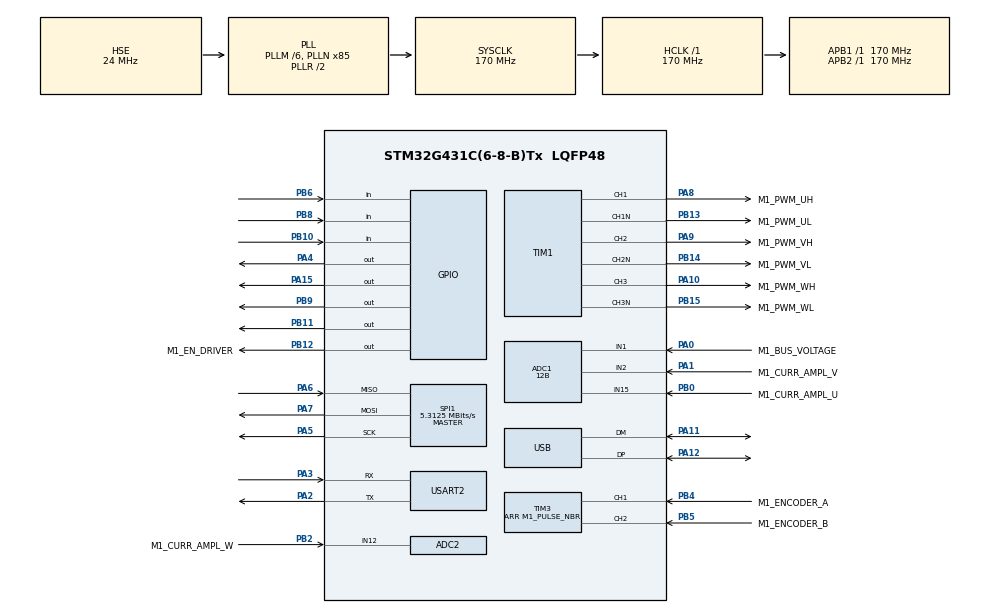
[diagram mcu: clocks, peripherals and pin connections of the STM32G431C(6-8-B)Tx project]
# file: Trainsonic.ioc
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ADC1.Channel-1\#ChannelRegularConversion=ADC_CHANNEL_1
ADC1.ClockPrescaler=ADC_CLOCK_ASYNC_DIV1
ADC1.ContinuousConvMode=DISABLE
ADC1.DMAContinuousRequests=DISABLE
ADC1.DataAlign=ADC_DATAALIGN_LEFT
ADC1.DiscontinuousConvMode=DISABLE
ADC1.EOCSelection=ADC_EOC_SINGLE_CONV
ADC1.EnableAnalogWatchDog1=false
ADC1.EnableAnalogWatchDog2=false
ADC1.EnableAnalogWatchDog3=false
ADC1.EnableInjectedConversion=ENABLE
ADC1.EnableRegularConversion=ENABLE
ADC1.ExternalTrigConv=ADC_SOFTWARE_START
ADC1.ExternalTrigConvEdge=ADC_EXTERNALTRIGCONVEDGE_NONE
ADC1.ExternalTrigInjecConv=ADC_EXTERNALTRIGINJEC_T1_TRGO
ADC1.ExternalTrigInjecConvEdge=ADC_EXTERNALTRIGINJECCONV_EDGE_RISING
ADC1.InjNumberOfConversion=2
ADC1.InjectedChannel-1\#ChannelInjectedConversion=ADC_CHANNEL_15
ADC1.InjectedChannel-2\#ChannelInjectedConversion=ADC_CHANNEL_2
ADC1.InjectedConvMode=None
ADC1.InjectedOffset-1\#ChannelInjectedConversion=0
ADC1.InjectedOffset-2\#ChannelInjectedConversion=0
ADC1.InjectedOffsetNumber-1\#ChannelInjectedConversion=ADC_OFFSET_NONE
ADC1.InjectedOffsetNumber-2\#ChannelInjectedConversion=ADC_OFFSET_NONE
ADC1.InjectedRank-1\#ChannelInjectedConversion=1
ADC1.InjectedRank-2\#ChannelInjectedConversion=2
ADC1.InjectedSamplingTime-1\#ChannelInjectedConversion=ADC_SAMPLETIME_6CYCLES_5
ADC1.InjectedSamplingTime-2\#ChannelInjectedConversion=ADC_SAMPLETIME_6CYCLES_5
ADC1.LowPowerAutoWait=DISABLE
ADC1.NbrOfConversion=1
ADC1.NbrOfConversionFlag=1
ADC1.Offset-1\#ChannelRegularConversion=0
ADC1.OffsetNumber-1\#ChannelRegularConversion=ADC_OFFSET_NONE
ADC1.Overrun=ADC_OVR_DATA_PRESERVED
ADC1.Rank-1\#ChannelRegularConversion=1
ADC1.Resolution=ADC_RESOLUTION_12B
ADC1.SamplingTime-1\#ChannelRegularConversion=ADC_SAMPLETIME_47CYCLES_5
ADC1.ScanConvMode=ADC_SCAN_ENABLE
ADC1.master=1
ADC2.ClockPrescaler=ADC_CLOCK_ASYNC_DIV1
ADC2.ContinuousConvMode=DISABLE
ADC2.DMAContinuousRequests=DISABLE
ADC2.DataAlign=ADC_DATAALIGN_LEFT
ADC2.DiscontinuousConvMode=DISABLE
ADC2.EOCSelection=ADC_EOC_SINGLE_CONV
ADC2.EnableAnalogWatchDog1=false
ADC2.EnableAnalogWatchDog2=false
ADC2.EnableAnalogWatchDog3=false
ADC2.EnableInjectedConversion=ENABLE
ADC2.EnableRegularConversion=DISABLE
ADC2.ExternalTrigInjecConv=ADC_EXTERNALTRIGINJEC_T1_TRGO
ADC2.ExternalTrigInjecConvEdge=ADC_EXTERNALTRIGINJECCONV_EDGE_RISING
ADC2.InjNumberOfConversion=2
ADC2.InjectedChannel-1\#ChannelInjectedConversion=ADC_CHANNEL_2
ADC2.InjectedChannel-2\#ChannelInjectedConversion=ADC_CHANNEL_12
ADC2.InjectedConvMode=None
ADC2.InjectedOffset-1\#ChannelInjectedConversion=0
ADC2.InjectedOffset-2\#ChannelInjectedConversion=0
ADC2.InjectedOffsetNumber-1\#ChannelInjectedConversion=ADC_OFFSET_NONE
ADC2.InjectedOffsetNumber-2\#ChannelInjectedConversion=ADC_OFFSET_NONE
ADC2.InjectedRank-1\#ChannelInjectedConversion=1
ADC2.InjectedRank-2\#ChannelInjectedConversion=2
ADC2.InjectedSamplingTime-1\#ChannelInjectedConversion=ADC_SAMPLETIME_6CYCLES_5
ADC2.InjectedSamplingTime-2\#ChannelInjectedConversion=ADC_SAMPLETIME_6CYCLES_5
ADC2.LowPowerAutoWait=DISABLE
ADC2.Overrun=ADC_OVR_DATA_PRESERVED
ADC2.Resolution=ADC_RESOLUTION_12B
ADC2.ScanConvMode=ADC_SCAN_ENABLE
ADC2.master=1
ExtraMW=MotorControl
ExtraMW.MotorControl.Config=MotorControl
ExtraMW.MotorControl.Mode=MotorControl
ExtraMW.MotorControl.Root=MCSDK_v6.4.2-Full/MotorControl
ExtraMW.MotorControl.Template=templates
FREERTOS.Tasks01=mediumFrequency,0,128,startMediumFrequencyTask,As weak,NULL,Dynamic,NULL,NULL;safety,1,128,StartSafetyTask,As external,NULL,Dynamic,NULL,NULL
FREERTOS.configUSE_NEWLIB_REENTRANT=1
Mcu.Family=STM32G4
Mcu.Name=STM32G431C(6-8-B)Tx
Mcu.Package=LQFP48
MotorControl.ADC_1_PERIPH=ADC1
MotorControl.ADC_2_PERIPH=ADC2
MotorControl.ADC_AHBPERIPH=RCC_AHBPeriph_ADC12
MotorControl.ADC_CLOCK_WB_DIV=1
MotorControl.ADC_PERIPH=ADC1
MotorControl.ADC_REFERENCE_VOLTAGE=3.3
MotorControl.BOARD=Trainsonic1
MotorControl.BUS_VOLTAGE_READING=true
MotorControl.CCMRAM_ENABLED=false
MotorControl.CLOCK_FREQUENCY=CPU_CLK_170_MHZ
MotorControl.CLOCK_SOURCE=EXTERNAL
MotorControl.CPU_CLK_170_MHZ=true
MotorControl.CTLBOARD_NAME=Trainsonic1
MotorControl.CUBE_MX_VER=6.17.0
MotorControl.CURRENT_READING_TOPOLOGY=THREE_SHUNT_INDEPENDENT_RESOURCES
MotorControl.CURR_SAMPLING_TIME=6
MotorControl.DBG_MCU_LOAD_MEASURE=false
MotorControl.DEBUG_DAC_FUNCTIONALITY_EN=false
MotorControl.DRIVES_NUMBER_SELECTION=SINGLEDRIVE
MotorControl.DRIVE_NUMBER=1
MotorControl.DRIVE_TYPE=FOC
MotorControl.ENCODER=true
MotorControl.ENCODER_AVAILABLE=true
MotorControl.ENCODER_PPR=1024
MotorControl.ENC_A_GPIO_PIN=LL_GPIO_PIN_4
MotorControl.ENC_A_GPIO_PORT=GPIOB
MotorControl.ENC_B_GPIO_PIN=LL_GPIO_PIN_5
MotorControl.ENC_B_GPIO_PORT=GPIOB
MotorControl.ENC_ICx_FILTER=128
MotorControl.ENC_INVERT_SPEED=false
MotorControl.ENC_TIMER_SELECTION=ENC_TIM3
MotorControl.ENC_USE_CH3=false
MotorControl.EN_DRIVER_AVAILABLE=true
MotorControl.EN_DRIVER_GPIO_PIN=LL_GPIO_PIN_12
MotorControl.EN_DRIVER_GPIO_PORT=GPIOB
MotorControl.EN_DRIVER_POLARITY=ACTIVE_HIGH
MotorControl.EXT_CLK_24_MHZ=true
MotorControl.EXT_CLOCK_FREQUENCY=EXT_CLK_24_MHZ
MotorControl.FEEDBACK_NET_FILTERING=false
MotorControl.FLASH_SIZE=128
MotorControl.HALL_SENSORS_AVAILABLE=false
MotorControl.HIGH_SIDE_IDLE_STATE=false
MotorControl.HWV_CS=ThreeShunt_AmplifiedCurrents
MotorControl.HWV_PWM=DrivingHighAndLowSidesAndMasterEnable
MotorControl.HW_COMPLEMENTED_LOW_SIDE=false
MotorControl.HW_DEAD_TIME_NS=400
MotorControl.IPs=CORDIC,NVIC,RCC,MotorControl,TIM1,ADC1,ADC2,TIM3,FREERTOS
MotorControl.LOW_MEMORY_FOOTPRINT_REG=false
MotorControl.LOW_SIDE_IDLE_STATE=false
MotorControl.LOW_SIDE_SIGNALS_ENABLING=LS_PWM_TIMER
MotorControl.M1_ALIGNMENT_ANGLE_DEG=90
MotorControl.M1_ALIGNMENT_DURATION=700
MotorControl.M1_AMPLIFICATION_GAIN=20
MotorControl.M1_ANGC={0,0,0,0,0,0,0,0}
MotorControl.M1_AUXILIARY_SPEED_SENSOR=NONE
MotorControl.M1_BOARD_MAX_CURRENT=8.2
MotorControl.M1_BUS_VOLTAGE_READING=true
MotorControl.M1_COMMUTATION_STEP_TIME_BUF_SIZE=12
MotorControl.M1_CONSTANT1_D=280527866
MotorControl.M1_CONSTANT1_Q=280527866
MotorControl.M1_CONSTANT2_QD=29234572
MotorControl.M1_CS_ADC_NUM=2
MotorControl.M1_CS_ADC_PHASE_SHARED=V
MotorControl.M1_CS_ADC_U=ADC1
MotorControl.M1_CS_ADC_W=ADC2
MotorControl.M1_CS_CHANNEL_SHARED=2
MotorControl.M1_CS_CHANNEL_U=15
MotorControl.M1_CS_CHANNEL_V=2
MotorControl.M1_CS_CHANNEL_W=12
MotorControl.M1_CURRENT_AMPLIFICATION_TOPO=EXTERNAL
MotorControl.M1_CURRENT_SENSING_TOPO=THREE_SHUNT
MotorControl.M1_CURR_SAMPLING_TIME=6
MotorControl.M1_DBG_OPEN_LOOP_ENABLE=false
MotorControl.M1_DC_CURRENT_RS_MEAS=8.2
MotorControl.M1_DEFAULT_CONTROL_MODE=STC_SPEED_MODE
MotorControl.M1_DEFAULT_FLUX_COMPONENT=0
MotorControl.M1_DEFAULT_TARGET_SPEED_RPM=252
MotorControl.M1_DEFAULT_TORQUE_COMPONENT=0
MotorControl.M1_DISCONTINUOUS_PWM=false
MotorControl.M1_DP_TOPOLOGY=NONE
MotorControl.M1_DRIVE_TYPE=FOC
MotorControl.M1_ENCODER_PPR=1024
MotorControl.M1_ENC_AVERAGING_FIFO_DEPTH=16
MotorControl.M1_ENC_A_GPIO_PIN=LL_GPIO_PIN_4
MotorControl.M1_ENC_A_GPIO_PORT=GPIOB
MotorControl.M1_ENC_B_GPIO_PIN=LL_GPIO_PIN_5
MotorControl.M1_ENC_B_GPIO_PORT=GPIOB
MotorControl.M1_ENC_ICx_FILTER=128
MotorControl.M1_ENC_TIMER_IRQ=TIM3
MotorControl.M1_ENC_TIMER_SELECTION=ENC_TIM3
MotorControl.M1_ENC_USE_CH3=false
MotorControl.M1_FEED_FORWARD_CURRENT_REG_ENABLING=false
MotorControl.M1_FINAL_I_ALIGNMENT=2
MotorControl.M1_FLUX_WEAKENING_ENABLING=false
MotorControl.M1_FW_KIDIV=32768
MotorControl.M1_FW_KI_GAIN=5000
MotorControl.M1_FW_KPDIV=32768
MotorControl.M1_FW_KP_GAIN=3000
MotorControl.M1_FW_VOLTAGE_REF=985
MotorControl.M1_HALL_PHASE_SHIFT=300
MotorControl.M1_HALL_SENSORS_PLACEMENT=DEGREES_120
MotorControl.M1_HIGH_SIDE_IDLE_STATE=false
MotorControl.M1_HW_DEAD_TIME_NS=400
MotorControl.M1_ICL_ENABLED=false
MotorControl.M1_ID_DEMAG=-8.2
MotorControl.M1_IQMAX=8.2
MotorControl.M1_LDLQ_RATIO=1.000
MotorControl.M1_LOW_SIDE_IDLE_STATE=false
MotorControl.M1_LOW_SIDE_SIGNALS_ENABLING=LS_PWM_TIMER
MotorControl.M1_LS=0.0014
MotorControl.M1_MAX_APPLICATION_SPEED=700
MotorControl.M1_MAX_MODULATION_INDEX=100
MotorControl.M1_MIN_APPLICATION_SPEED=0
MotorControl.M1_MOTOR_MAX_SPEED_RPM=700
MotorControl.M1_MOTOR_NAME=Trainsonic
MotorControl.M1_MOTOR_RATED_FLUX=0.121004793
MotorControl.M1_MOTOR_VOLTAGE_CONSTANT=49.4
MotorControl.M1_MTPA_ENABLING=false
MotorControl.M1_NOMINAL_BUS_VOLTAGE_V=60
MotorControl.M1_NOMINAL_CURRENT=8.2
MotorControl.M1_OCP_TOPOLOGY=NONE
MotorControl.M1_OFST={0,0,0,0,0,0,0,0}
MotorControl.M1_ON_OVER_VOLTAGE=TURN_ON_LOW_SIDES
MotorControl.M1_OVERMODULATION=false
MotorControl.M1_OVP_THRESHOLD_HIGH=60.0
MotorControl.M1_OV_VOLTAGE_PROT_ENABLING=true
MotorControl.M1_OV_VOLTAGE_THRESHOLD_V=60.0
MotorControl.M1_PID_FLUX_KD_DEFAULT=100
MotorControl.M1_PID_FLUX_KI_DEFAULT=2501
MotorControl.M1_PID_FLUX_KP_DEFAULT=2365
MotorControl.M1_PID_SPEED_KD_DEFAULT=0
MotorControl.M1_PID_SPEED_KI_DEFAULT=5
MotorControl.M1_PID_SPEED_KP_DEFAULT=2601
MotorControl.M1_PID_TORQUE_KD_DEFAULT=100
MotorControl.M1_PID_TORQUE_KI_DEFAULT=2501
MotorControl.M1_PID_TORQUE_KP_DEFAULT=2365
MotorControl.M1_POLE_PAIR_NUM=20
MotorControl.M1_POSITION_CTRL_ENABLING=false
MotorControl.M1_POTENTIOMETER_ENABLE=false
MotorControl.M1_POWERBOARD_NAME=Trainsonic1
MotorControl.M1_PWM_CHARGE_BOOT_CAP_DUTY_CYCLES=0.000
MotorControl.M1_PWM_CHARGE_BOOT_CAP_MS=10
MotorControl.M1_PWM_DRIVER_PN=DRV8353S
MotorControl.M1_PWM_FREQUENCY=16000
MotorControl.M1_PWM_TIMER_BRK_IRQ=TIM1_BRK_TIM15
MotorControl.M1_PWM_TIMER_SELECTION=PWM_TIM1
MotorControl.M1_PWM_TIMER_UP_IRQ=TIM1_UP_TIM16
MotorControl.M1_REGULATION_EXECUTION_RATE=1
MotorControl.M1_RS=0.74
MotorControl.M1_RSHUNT=0.005
MotorControl.M1_SEGDIV=0
MotorControl.M1_SHARED_SIGNAL_ENABLE=false
MotorControl.M1_SPD_DIFFERENTIAL_TERM_ENABLING=false
MotorControl.M1_SPEED_LOOP_FREQUENCY_HZ=1000
MotorControl.M1_SPEED_SENSOR=QUAD_ENCODER
MotorControl.M1_SP_KDDIV=16
MotorControl.M1_SP_KIDIV=16384
MotorControl.M1_SP_KPDIV=8192
MotorControl.M1_SS_MEAS_ERRORS_BEFORE_FAULTS=3
MotorControl.M1_SW_DEADTIME_NS=400
MotorControl.M1_TEMPERATURE_READING=false
MotorControl.M1_TF_KDDIV=8192
MotorControl.M1_TF_KIDIV=16384
MotorControl.M1_TF_KPDIV=512
MotorControl.M1_TNOISE_NS=100
MotorControl.M1_TRISE_NS=100
MotorControl.M1_UD_VOLTAGE_THRESHOLD_V=20.0
MotorControl.M1_USE_INTERNAL_OPAMP=false
MotorControl.M1_UV_VOLTAGE_PROT_ENABLING=true
MotorControl.M1_VBUS_ADC=ADC1
MotorControl.M1_VBUS_ADC_SAMPLING_TIME=47
MotorControl.M1_VBUS_CHANNEL=ADC_CHANNEL_1
MotorControl.M1_VBUS_PARTITIONING_FACTOR=0.0411
MotorControl.MAX_READABLE_CURRENT=16.5
MotorControl.MCP_EN=false
MotorControl.MCU=STM32G431CB
MotorControl.MCU_FAMILY=STM32G4
MotorControl.MCU_LINE=STM32G4x1
MotorControl.MCU_NAME=STM32G431C(6-8-B)Tx
MotorControl.MCU_PACKAGE=LQFP48
MotorControl.MCU_TYPE=STM32G431CB
MotorControl.MCU_USERNAME=STM32G431CBTx
MotorControl.MC_WORKBENCH_VERSION=6.4.2
MotorControl.MOTOR_PROFILER=false
MotorControl.MOTOR_TYPE=PMSM
MotorControl.ON_OVER_VOLTAGE=TURN_ON_LOW_SIDES
MotorControl.OV_VOLTAGE_PROT_ENABLING=true
MotorControl.PHASE_UH_GPIO_PIN=LL_GPIO_PIN_8
MotorControl.PHASE_UH_GPIO_PORT=GPIOA
MotorControl.PHASE_UH_POLARITY=H_ACTIVE_HIGH
MotorControl.PHASE_UL_GPIO_PIN=LL_GPIO_PIN_13
MotorControl.PHASE_UL_GPIO_PORT=GPIOB
MotorControl.PHASE_UL_POLARITY=L_ACTIVE_HIGH
MotorControl.PHASE_U_CURR_ADC=ADC1
MotorControl.PHASE_U_CURR_CHANNEL=ADC_CHANNEL_15
MotorControl.PHASE_U_GPIO_PIN=LL_GPIO_PIN_0
MotorControl.PHASE_U_GPIO_PORT=GPIOB
MotorControl.PHASE_U_PWM_CHANNEL=TIM_Channel_1
MotorControl.PHASE_VH_GPIO_PIN=LL_GPIO_PIN_9
MotorControl.PHASE_VH_GPIO_PORT=GPIOA
MotorControl.PHASE_VH_POLARITY=H_ACTIVE_HIGH
MotorControl.PHASE_VL_GPIO_PIN=LL_GPIO_PIN_14
MotorControl.PHASE_VL_GPIO_PORT=GPIOB
MotorControl.PHASE_VL_POLARITY=L_ACTIVE_HIGH
MotorControl.PHASE_V_CURR_ADC=ADC1
MotorControl.PHASE_V_CURR_CHANNEL=ADC_CHANNEL_2
MotorControl.PHASE_V_GPIO_PIN=LL_GPIO_PIN_1
MotorControl.PHASE_V_GPIO_PORT=GPIOA
MotorControl.PHASE_V_PWM_CHANNEL=TIM_Channel_2
MotorControl.PHASE_V_S_CURR_ADC=ADC2
MotorControl.PHASE_V_S_CURR_CHANNEL=ADC_CHANNEL_2
MotorControl.PHASE_V_S_GPIO_PIN=LL_GPIO_PIN_1
MotorControl.PHASE_V_S_GPIO_PORT=GPIOA
MotorControl.PHASE_WH_GPIO_PIN=LL_GPIO_PIN_10
MotorControl.PHASE_WH_GPIO_PORT=GPIOA
MotorControl.PHASE_WH_POLARITY=H_ACTIVE_HIGH
MotorControl.PHASE_WL_GPIO_PIN=LL_GPIO_PIN_15
MotorControl.PHASE_WL_GPIO_PORT=GPIOB
MotorControl.PHASE_WL_POLARITY=L_ACTIVE_HIGH
MotorControl.PHASE_W_CURR_ADC=ADC2
MotorControl.PHASE_W_CURR_CHANNEL=ADC_CHANNEL_12
MotorControl.PHASE_W_GPIO_PIN=LL_GPIO_PIN_2
MotorControl.PHASE_W_GPIO_PORT=GPIOB
MotorControl.PHASE_W_PWM_CHANNEL=TIM_Channel_3
MotorControl.POTENTIOMETER_READING=false
MotorControl.PWM_FREQUENCY=16000
MotorControl.PWM_TIMER_SELECTION=PWM_TIM1
MotorControl.REGULATION_EXECUTION_RATE=1
MotorControl.RTOS=FREERTOS
MotorControl.RTOS_IRQ_NAME_WB2MX=TIM6_DAC_IRQn
MotorControl.RTOS_TIMER=TIM6
MotorControl.RTOS_USE_IRQ=false
MotorControl.R_BRAKE_SWITCH_OFF_THRES_V=48
MotorControl.SINGLEDRIVE=true
MotorControl.SPD_DIFFERENTIAL_TERM_ENABLING=false
MotorControl.SPEED_SENSOR_SELECTION=ENCODER
MotorControl.START_STOP_BTN=false
MotorControl.STM32G431CB=true
MotorControl.SW_DEADTIME_NS=400
MotorControl.TEMPERATURE_READING=false
MotorControl.TFDIFFERENTIAL_TERM_ENABLING=false
MotorControl.THREE_SHUNT_INDEPENDENT_RESOURCES=true
MotorControl.TRISE_NS=100
MotorControl.USE_3OPAMPS=false
MotorControl.USE_INTERNAL_OPAMP=false
MotorControl.UV_VOLTAGE_PROT_ENABLING=true
MotorControl.VBUS_ADC=ADC1
MotorControl.VBUS_ADC_SAMPLING_TIME=47
MotorControl.VBUS_CHANNEL=ADC_CHANNEL_1
MotorControl.VBUS_GPIO_PIN=LL_GPIO_PIN_0
MotorControl.VBUS_GPIO_PORT=GPIOA
MotorControl.WB_MX_HEAPSIZE=0x200
MotorControl.WB_MX_STACKSIZE=0x400
MotorControl.WB_MX_TRUSTZONE_AVAILABLE=false
MotorControl.WB_UI_CUTOFF_FREQUENCY=6000
MotorControl.WB_UI_ENCODER_HAS_INDEX_PIN=true
MotorControl.WB_UI_FLUX_TARGET=0
MotorControl.WB_UI_FRICTION=0.49
MotorControl.WB_UI_INERTIA=0.55
MotorControl.WB_UI_MAGNETIC_STRUCTURE=SM-PMSM
MotorControl.WB_UI_MAX_CURRENT=8.2
MotorControl.WB_UI_MAX_NOMINAL_DC_VOLTAGE=60
MotorControl.WB_UI_MAX_PWMFREQUENCY=25000
MotorControl.WB_UI_MOTOR_DESCRIPTION=48V
MotorControl.WB_UI_PW_BOARD_MAX_RATED_CURRENT=8.2
MotorControl.WB_UI_PW_BOARD_MAX_VOLTAGE=70
MotorControl.WB_UI_PW_BOARD_MIN_VOLTAGE=20
MotorControl.WB_UI_VPOL=0
MotorControl.WB_to_Mx_template_version=25-05-06
MotorControl.WB_to_Mx_version=6.4.2
NVIC.ADC1_2_IRQn=true\:2\:0\:true\:true\:false\:3\:false\:true\:true\:true
NVIC.PriorityGroup=NVIC_PRIORITYGROUP_4
NVIC.TIM1_BRK_TIM15_IRQn=true\:4\:0\:true\:true\:false\:1\:false\:true\:true\:true
NVIC.TIM1_UP_TIM16_IRQn=true\:0\:0\:true\:true\:false\:2\:false\:true\:true\:true
NVIC.TIM3_IRQn=true\:3\:0\:true\:true\:false\:4\:false\:true\:true\:true
NVIC.TIM6_DAC_IRQn=true\:0\:0\:false\:false\:true\:false\:false\:true\:true
NVIC.TimeBase=TIM6_DAC_IRQn
NVIC.TimeBaseIP=TIM6
NVIC.USB_LP_IRQn=true\:5\:0\:false\:false\:true\:true\:false\:true\:true
PA0.GPIO_Label=M1_BUS_VOLTAGE
PA0.Mode=IN1-Single-Ended
PA0.Signal=ADC1_IN1
PA1.GPIO_Label=M1_CURR_AMPL_V
PA1.Signal=SharedAnalog_PA1
PA10.GPIO_Label=M1_PWM_WH
PA10.GPIO_PuPd=GPIO_PULLDOWN
PA10.GPIO_Speed=GPIO_SPEED_FREQ_HIGH
PA10.Signal=S_TIM1_CH3
PA11.Mode=Device
PA11.Signal=USB_DM
PA12.Mode=Device
PA12.Signal=USB_DP
PA15.Signal=GPIO_Output
PA2.Mode=Asynchronous
PA2.Signal=USART2_TX
PA3.Mode=Asynchronous
PA3.Signal=USART2_RX
PA4.PinState=GPIO_PIN_SET
PA4.Signal=GPIO_Output
PA5.Mode=Full_Duplex_Master
PA5.Signal=SPI1_SCK
PA6.Mode=Full_Duplex_Master
PA6.Signal=SPI1_MISO
PA7.Mode=Full_Duplex_Master
PA7.Signal=SPI1_MOSI
PA8.GPIO_Label=M1_PWM_UH
PA8.GPIO_PuPd=GPIO_PULLDOWN
PA8.GPIO_Speed=GPIO_SPEED_FREQ_HIGH
PA8.Signal=S_TIM1_CH1
PA9.GPIO_Label=M1_PWM_VH
PA9.GPIO_PuPd=GPIO_PULLDOWN
PA9.GPIO_Speed=GPIO_SPEED_FREQ_HIGH
PA9.Signal=S_TIM1_CH2
PB0.GPIO_Label=M1_CURR_AMPL_U
PB0.Mode=IN15-Single-Ended
PB0.Signal=ADC1_IN15
PB10.Signal=GPIO_Input
PB11.Signal=GPIO_Output
PB12.GPIO_Label=M1_EN_DRIVER
PB12.GPIO_PuPd=GPIO_PULLUP
PB12.PinState=GPIO_PIN_SET
PB12.Signal=GPIO_Output
PB13.GPIO_Label=M1_PWM_UL
PB13.GPIO_PuPd=GPIO_PULLDOWN
PB13.GPIO_Speed=GPIO_SPEED_FREQ_HIGH
PB13.Mode=PWM Generation1 CH1 CH1N
PB13.Signal=TIM1_CH1N
PB14.GPIO_Label=M1_PWM_VL
PB14.GPIO_PuPd=GPIO_PULLDOWN
PB14.GPIO_Speed=GPIO_SPEED_FREQ_HIGH
PB14.Mode=PWM Generation2 CH2 CH2N
PB14.Signal=TIM1_CH2N
PB15.GPIO_Label=M1_PWM_WL
PB15.GPIO_PuPd=GPIO_PULLDOWN
PB15.GPIO_Speed=GPIO_SPEED_FREQ_HIGH
PB15.Mode=PWM Generation3 CH3 CH3N
PB15.Signal=TIM1_CH3N
PB2.GPIO_Label=M1_CURR_AMPL_W
PB2.Mode=IN12-Single-Ended
PB2.Signal=ADC2_IN12
PB4.GPIO_Label=M1_ENCODER_A
PB4.Signal=S_TIM3_CH1
PB5.GPIO_Label=M1_ENCODER_B
PB5.Signal=S_TIM3_CH2
PB6.Signal=GPIO_Input
PB8-BOOT0.Signal=GPIO_Input
PB9.Signal=GPIO_Output
PF0-OSC_IN.Mode=HSE-External-Oscillator
PF0-OSC_IN.Signal=RCC_OSC_IN
PF1-OSC_OUT.Mode=HSE-External-Oscillator
PF1-OSC_OUT.Signal=RCC_OSC_OUT
ProjectManager.HeapSize=0x200
ProjectManager.StackSize=0x400
ProjectManager.TargetToolchain=STM32CubeIDE
RCC.ADC12CLockSelection=RCC_ADC12CLKSOURCE_PLL
RCC.ADC12Freq_Value=42500000
RCC.AHBFreq_Value=170000000
RCC.APB1Freq_Value=170000000
RCC.APB1TimFreq_Value=170000000
RCC.APB2Freq_Value=170000000
RCC.APB2TimFreq_Value=170000000
RCC.CK48CLockSelection=RCC_USBCLKSOURCE_HSI48
RCC.CortexFreq_Value=170000000
RCC.EXTERNAL_CLOCK_VALUE=12288000
RCC.EnbaleCSS=true
RCC.HCLKFreq_Value=170000000
RCC.HSE_VALUE=24000000
RCC.HSI48_VALUE=48000000
RCC.HSI_VALUE=16000000
RCC.LSE_VALUE=32768
RCC.PLLM=RCC_PLLM_DIV6
RCC.PLLN=85
RCC.PLLP=RCC_PLLP_DIV8
RCC.PLLSourceVirtual=RCC_PLLSOURCE_HSE
RCC.PREFETCH_ENABLE=1
RCC.SYSCLKFreq_VALUE=170000000
RCC.SYSCLKSource=RCC_SYSCLKSOURCE_PLLCLK
RCC.USBFreq_Value=48000000
RCC.VCOOutputFreq_Value=340000000
SH.S_TIM1_CH1.0=TIM1_CH1,PWM Generation1 CH1 CH1N
SH.S_TIM1_CH2.0=TIM1_CH2,PWM Generation2 CH2 CH2N
SH.S_TIM1_CH3.0=TIM1_CH3,PWM Generation3 CH3 CH3N
SH.S_TIM3_CH1.0=TIM3_CH1,Encoder_Interface
SH.S_TIM3_CH2.0=TIM3_CH2,Encoder_Interface
SH.SharedAnalog_PA1.0=ADC1_IN2,IN2-Single-Ended
SH.SharedAnalog_PA1.1=ADC2_IN2,IN2-Single-Ended
SPI1.BaudRatePrescaler=SPI_BAUDRATEPRESCALER_32
SPI1.CLKPhase=SPI_PHASE_2EDGE
SPI1.CalculateBaudRate=5.3125 MBits/s
SPI1.DataSize=SPI_DATASIZE_16BIT
SPI1.Direction=SPI_DIRECTION_2LINES
SPI1.Mode=SPI_MODE_MASTER
SPI1.VirtualType=VM_MASTER
TIM1.AutoReloadPreload=TIM_AUTORELOAD_PRELOAD_DISABLE
TIM1.AutomaticOutput=TIM_AUTOMATICOUTPUT_DISABLE
TIM1.Break2Filter=3
TIM1.Break2Polarity=TIM_BREAK2POLARITY_HIGH
TIM1.Break2State=TIM_BREAK2_DISABLE
TIM1.BreakFilter=0
TIM1.BreakPolarity=TIM_BREAKPOLARITY_HIGH
TIM1.BreakState=TIM_BREAK_DISABLE
TIM1.Channel=TIM_CHANNEL_4
TIM1.Channel-PWM\ Generation1\ CH1\ CH1N=TIM_CHANNEL_1
TIM1.Channel-PWM\ Generation2\ CH2\ CH2N=TIM_CHANNEL_2
TIM1.Channel-PWM\ Generation3\ CH3\ CH3N=TIM_CHANNEL_3
TIM1.Channel-PWM\ Generation4\ No\ Output=TIM_CHANNEL_4
TIM1.ClearInputSource=TIM_CLEARINPUTSOURCE_NONE
TIM1.ClockDivision=TIM_CLOCKDIVISION_DIV2
TIM1.CounterMode=TIM_COUNTERMODE_CENTERALIGNED1
TIM1.DeadTime=((DEAD_TIME_COUNTS) / 2)
TIM1.LockLevel=TIM_LOCKLEVEL_OFF
TIM1.OC1Preload_PWM=ENABLE
TIM1.OC2Preload_PWM=ENABLE
TIM1.OC3Preload_PWM=ENABLE
TIM1.OC4Preload_PWM=ENABLE
TIM1.OCFastMode_PWM=TIM_OCFAST_DISABLE
TIM1.OCIdleState_1=TIM_OCIDLESTATE_RESET
TIM1.OCIdleState_2=TIM_OCIDLESTATE_RESET
TIM1.OCIdleState_3=TIM_OCIDLESTATE_RESET
TIM1.OCIdleState_4=TIM_OCIDLESTATE_RESET
TIM1.OCMode_PWM-PWM\ Generation1\ CH1\ CH1N=TIM_OCMODE_PWM1
TIM1.OCMode_PWM-PWM\ Generation2\ CH2\ CH2N=TIM_OCMODE_PWM1
TIM1.OCMode_PWM-PWM\ Generation3\ CH3\ CH3N=TIM_OCMODE_PWM1
TIM1.OCMode_PWM-PWM\ Generation4\ No\ Output=TIM_OCMODE_PWM2
TIM1.OCNIdleState_1=TIM_OCNIDLESTATE_RESET
TIM1.OCNIdleState_2=TIM_OCNIDLESTATE_RESET
TIM1.OCNIdleState_3=TIM_OCNIDLESTATE_RESET
TIM1.OCNPolarity_1=TIM_OCNPOLARITY_HIGH
TIM1.OCNPolarity_2=TIM_OCNPOLARITY_HIGH
TIM1.OCNPolarity_3=TIM_OCNPOLARITY_HIGH
TIM1.OCPolarity_1=TIM_OCPOLARITY_HIGH
TIM1.OCPolarity_2=TIM_OCPOLARITY_HIGH
TIM1.OCPolarity_3=TIM_OCPOLARITY_HIGH
TIM1.OCPolarity_4=TIM_OCPOLARITY_HIGH
TIM1.OffStateIDLEMode=TIM_OSSI_ENABLE
TIM1.OffStateRunMode=TIM_OSSR_ENABLE
TIM1.PeriodNoDither=((PWM_PERIOD_CYCLES) / 2)
TIM1.Prescaler=((TIM_CLOCK_DIVIDER) - 1)
TIM1.PulseNoDither_1=((PWM_PERIOD_CYCLES) / 4)
TIM1.PulseNoDither_2=((PWM_PERIOD_CYCLES) / 4)
TIM1.PulseNoDither_3=((PWM_PERIOD_CYCLES) / 4)
TIM1.PulseNoDither_4=(((PWM_PERIOD_CYCLES) / 2) - (HTMIN))
TIM1.RepetitionCounter=(REP_COUNTER)
TIM1.SourceBRK2DigInput=TIM_BREAKINPUTSOURCE_DISABLE
TIM1.SourceBRKDigInput=TIM_BREAKINPUTSOURCE_DISABLE
TIM1.TIM_MasterOutputTrigger=TIM_TRGO_OC4REF
TIM1.TIM_MasterOutputTrigger2=TIM_TRGO2_RESET
TIM1.TIM_MasterSlaveMode=TIM_MASTERSLAVEMODE_DISABLE
TIM1.TIM_SlaveMode=TIM_SLAVEMODE_TRIGGER
TIM3.EncoderMode=TIM_ENCODERMODE_TI12
TIM3.IC1Filter=M1_ENC_IC_FILTER
TIM3.IC1Polarity=TIM_ICPOLARITY_RISING
TIM3.IC2Filter=M1_ENC_IC_FILTER
TIM3.IC2Polarity=TIM_ICPOLARITY_RISING
TIM3.PeriodNoDither=M1_PULSE_NBR
USART2.VirtualMode-Asynchronous=VM_ASYNC
USB_DEVICE.CLASS_NAME_FS=CDC
USB_DEVICE.VirtualMode=Cdc
USB_DEVICE.VirtualModeFS=Cdc_FS
VP_CORDIC_VS_CORDIC.Mode=CORDIC_Activate
VP_FREERTOS_VS_CMSIS_V1.Mode=CMSIS_V1
VP_MotorControl_MC_ENABLED.Mode=Enabled
VP_RCC_VS_USB.Mode=USB_FS
VP_SYS_VS_DBSignals.Mode=DisableDeadBatterySignals
VP_SYS_VS_tim6.Mode=TIM6
VP_TIM1_VS_no_output4.Mode=PWM Generation4 No Output
VP_USB_DEVICE_VS_USB_DEVICE_CDC_FS.Mode=CDC_FS
board=custom

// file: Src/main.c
/* USER CODE BEGIN Header */
/**
  ******************************************************************************
  * @file           : main.c
  * @brief          : Main program body
  ******************************************************************************
  * @attention
  *
  * Copyright (c) 2026 STMicroelectronics.
  * All rights reserved.
  *
  * This software is licensed under terms that can be found in the LICENSE file
  * in the root directory of this software component.
  * If no LICENSE file comes with this software, it is provided AS-IS.
  *
  ******************************************************************************
  */
/* USER CODE END Header */
#include "main.h"
#include "cmsis_os.h"
#include "usb_device.h"

/* USER CODE BEGIN Includes */
#include "drv8353.h"             /* DRV8353RS gate driver (bit-banged SPI)     */
#include "log.h"                 /* USB-CDC logging                            */
#include "mc_api.h"              /* motor command API                          */
#include "parameters_conversion.h" /* CURRENT_CONV_FACTOR(_INV), SPEED_UNIT    */
#include "mc_config_common.h"    /* BusVoltageSensor_M1 for Vbus logging       */
#include "mc_config.h"           /* FOCVars / pwmcHandle for loop diagnostics  */
#include "usb_device.h"          /* MX_USB_Device_Init -- see appTask note      */
#include "as5047.h"              /* AS5047P absolute encoder (SPI1) -- now USED for the FOC angle */
#include "cogg_table.h"          /* COGG_NBINS -- anti-cogging map dump                       */
#include "esp_link.h"            /* ESP32 <-> STM32 UART link on USART2 (PA2/PA3)             */
/* USER CODE END Includes */

/* USER CODE BEGIN PD */
/* ENCODER-ONLY bring-up: when 1, the motor is NEVER started (no torque, no
   commutation, no PWM). appTask just streams the raw AS5047 reading continuously
   so you can verify the encoder/magnet in isolation by turning the shaft by hand.
   Set back to 0 for normal motor operation. */
#define ENC_ONLY                0
#define BOOT_TORQUE_REF_A       0.0f    /* torque-control boot current (A); 0 = rotor holds at rest for a clean d-axis step capture. Raise only if the shaft is mechanically loaded/held. */
#define BOOT_TORQUE_RAMP_MS     500     /* 0 -> target ramp duration (ms)       */
#define STEP_MODE               0       /* 'g' test: 0 = current-loop step, 1 = speed-loop step, 2 = Iq-ripple @ const speed
                                           STEP_MODE 1 BOOTS in SPEED control to SPEED_BASE_RPM (safe, won't run away). */
/* --- Iq-ripple capture (STEP_MODE 2): run steady, capture Iq for an FFT --- */
#define RIPPLE_SPEED_RPM        150     /* constant speed for the ripple capture (rpm) */
#define RIPPLE_DECIM            10      /* HF/this = 2.5 kHz; 512 samp = ~205 ms (Nyquist 1.25 kHz) */
/* --- current-loop step (STEP_MODE 0) --- */
#define STEP_AXIS_Q             0       /* axis: 1 = q (torque, rotor spins), 0 = d (rotor holds) */
#define STEP_FROM_A             0.2f    /* step start current (A) */
#define STEP_TO_A               1.0f    /* step end current (A) */
#define STEP_BASELINE_MS        3       /* current-step baseline before the step (ms) */
#define STEP_DECIM              1       /* must match STEP_DECIM in mc_tasks_foc.c (log-rate display only) */
/* --- speed-loop step (STEP_MODE 1) --- captured at 1 kHz over 512 ms --- */
#define SPEED_BASE_RPM          50      /* speed-step baseline (rpm); moving baseline avoids standstill stiction */
#define SPEED_STEP_RPM          150     /* speed-step target (rpm); keep < ~400 (30 V voltage wall) */
#define SPEED_BASELINE_MS       40      /* speed-step baseline captured before the step (ms) */
#define SPEED_CAP_DECIM         4       /* must match SPEED_CAP_DECIM in mc_tasks_foc.c: 1kHz/4 = 250 Hz -> 512 samp = ~2 s */
#define BOOT_SPEED_RPM          60      /* speed-mode boot target (rpm); low for clean INL capture */
#define BOOT_SPEED_RAMP_MS      2000    /* 0 -> target speed ramp duration (ms) */
#define APP_LOOP_PERIOD_MS      50U     /* app-task yield / health-tick interval (INL hold + [m] line rate gate) */
#define MOTOR_LOG_PERIOD_MS     50U     /* periodic [m] status line interval: every app-task loop (20 Hz --
                                           bounded by APP_LOOP_PERIOD_MS; raise to log less) */

/* Open-loop forced commutation for a CLEAN INL capture (method A). When 1, boot
   in torque mode with a fixed holding current and rotate the electrical field at
   a constant commanded speed -- the encoder is OUT of the loop, so the captured
   angle vs the constant ramp is free of speed-loop ripple. Set 0 for normal run. */
#define BOOT_OPENLOOP           0       /* 0 = normal closed-loop (encoder in loop)        */
#define BOOT_OL_SPEED_RPM       30      /* commanded mech speed (rpm); low for clean INL  */
#define BOOT_OL_IQ_A            4.0f    /* holding q-current (A); raise if the rotor slips */
/* USER CODE END PD */

ADC_HandleTypeDef hadc1;
ADC_HandleTypeDef hadc2;

CORDIC_HandleTypeDef hcordic;

SPI_HandleTypeDef hspi1;

TIM_HandleTypeDef htim1;
TIM_HandleTypeDef htim3;

UART_HandleTypeDef huart2;

osThreadId mediumFrequencyHandle;
osThreadId safetyHandle;
/* USER CODE BEGIN PV */
osThreadId appTaskHandle;        /* boot diagnostics + auto-start + status log  */
static void StartAppTask(void const *argument);
static const char *mc_state_name(MCI_State_t state);
static void log_mc_faults(const char *label, uint16_t faults);
static void motor_status_log(void);
/* Encoder index (Z) on PB3 -> reset TIM3 count once per mech rev (cancels ABI
   miscount drift). Impl in Ropetow_IndexInit()/EXTI3_IRQHandler() (USER CODE 4). */
static void Ropetow_IndexInit(void);
static volatile uint16_t g_idx_cnt    = 0U;  /* TIM3 count captured at the index   */
static volatile uint8_t  g_idx_have   = 0U;  /* index reference captured this run?  */
static volatile uint32_t g_idx_events = 0U;  /* diag: index pulses handled          */
/* USER CODE END PV */

void SystemClock_Config(void);
static void MX_GPIO_Init(void);
static void MX_ADC1_Init(void);
static void MX_ADC2_Init(void);
static void MX_CORDIC_Init(void);
static void MX_TIM1_Init(void);
static void MX_TIM3_Init(void);
static void MX_SPI1_Init(void);
static void MX_USART2_UART_Init(void);
void startMediumFrequencyTask(void const * argument);
extern void StartSafetyTask(void const * argument);

static void MX_NVIC_Init(void);

int main(void)
{

  /* MCU Configuration--------------------------------------------------------*/

  /* Reset of all peripherals, Initializes the Flash interface and the Systick. */
  HAL_Init();

  /* Configure the system clock */
  SystemClock_Config();

  /* Initialize all configured peripherals */
  MX_GPIO_Init();
  MX_ADC1_Init();
  MX_ADC2_Init();
  MX_CORDIC_Init();
  MX_TIM1_Init();
  MX_TIM3_Init();
  MX_MotorControl_Init();
  MX_SPI1_Init();
  MX_USART2_UART_Init();

  /* Initialize interrupts */
  MX_NVIC_Init();

  /* Create the thread(s) */
  /* definition and creation of mediumFrequency */
  osThreadDef(mediumFrequency, startMediumFrequencyTask, osPriorityNormal, 0, 128);
  mediumFrequencyHandle = osThreadCreate(osThread(mediumFrequency), NULL);

  /* definition and creation of safety */
  osThreadDef(safety, StartSafetyTask, osPriorityAboveNormal, 0, 128);
  safetyHandle = osThreadCreate(osThread(safety), NULL);

  /* USER CODE BEGIN RTOS_THREADS */
  /* Application task: configures the DRV8353, dumps boot diagnostics, starts
     the motor, and streams periodic status over USB CDC. Low priority so it
     never disturbs the medium-frequency / safety MC tasks; larger stack for
     the printf-style logger. */
  osThreadDef(appTask, StartAppTask, osPriorityLow, 0, 512);
  appTaskHandle = osThreadCreate(osThread(appTask), NULL);
  /* USER CODE END RTOS_THREADS */

  /* Start scheduler */
  osKernelStart();

  /* We should never get here as control is now taken by the scheduler */

  /* Infinite loop */
  while (1)
  {

  }
}

void SystemClock_Config(void)
{
  RCC_OscInitTypeDef RCC_OscInitStruct = {0};
  RCC_ClkInitTypeDef RCC_ClkInitStruct = {0};
  RCC_CRSInitTypeDef pInit = {0};

  /** Configure the main internal regulator output voltage
  */
  HAL_PWREx_ControlVoltageScaling(PWR_REGULATOR_VOLTAGE_SCALE1_BOOST);

  /** Initializes the RCC Oscillators according to the specified parameters
  * in the RCC_OscInitTypeDef structure.
  */
  RCC_OscInitStruct.OscillatorType = RCC_OSCILLATORTYPE_HSI48|RCC_OSCILLATORTYPE_HSE;
  RCC_OscInitStruct.HSEState = RCC_HSE_ON;
  RCC_OscInitStruct.HSI48State = RCC_HSI48_ON;
  RCC_OscInitStruct.PLL.PLLState = RCC_PLL_ON;
  RCC_OscInitStruct.PLL.PLLSource = RCC_PLLSOURCE_HSE;
  RCC_OscInitStruct.PLL.PLLM = RCC_PLLM_DIV6;
  RCC_OscInitStruct.PLL.PLLN = 85;
  RCC_OscInitStruct.PLL.PLLP = RCC_PLLP_DIV8;
  RCC_OscInitStruct.PLL.PLLQ = RCC_PLLQ_DIV2;
  RCC_OscInitStruct.PLL.PLLR = RCC_PLLR_DIV2;
  if (HAL_RCC_OscConfig(&RCC_OscInitStruct) != HAL_OK)
  {
    Error_Handler();
  }

  /** Initializes the CPU, AHB and APB buses clocks
  */
  RCC_ClkInitStruct.ClockType = RCC_CLOCKTYPE_HCLK|RCC_CLOCKTYPE_SYSCLK
                              |RCC_CLOCKTYPE_PCLK1|RCC_CLOCKTYPE_PCLK2;
  RCC_ClkInitStruct.SYSCLKSource = RCC_SYSCLKSOURCE_PLLCLK;
  RCC_ClkInitStruct.AHBCLKDivider = RCC_SYSCLK_DIV1;
  RCC_ClkInitStruct.APB1CLKDivider = RCC_HCLK_DIV1;
  RCC_ClkInitStruct.APB2CLKDivider = RCC_HCLK_DIV1;

  if (HAL_RCC_ClockConfig(&RCC_ClkInitStruct, FLASH_LATENCY_4) != HAL_OK)
  {
    Error_Handler();
  }

  /** Enables the Clock Security System
  */
  HAL_RCC_EnableCSS();

  /** Enable the SYSCFG APB clock
  */
  __HAL_RCC_CRS_CLK_ENABLE();

  /** Configures CRS
  */
  pInit.Prescaler = RCC_CRS_SYNC_DIV1;
  pInit.Source = RCC_CRS_SYNC_SOURCE_USB;
  pInit.Polarity = RCC_CRS_SYNC_POLARITY_RISING;
  pInit.ReloadValue = __HAL_RCC_CRS_RELOADVALUE_CALCULATE(48000000,1000);
  pInit.ErrorLimitValue = 34;
  pInit.HSI48CalibrationValue = 32;

  HAL_RCCEx_CRSConfig(&pInit);
}

/**
  * @brief NVIC Configuration.
  * @retval None
  */
static void MX_NVIC_Init(void)
{
  /* TIM1_BRK_TIM15_IRQn interrupt configuration */
  HAL_NVIC_SetPriority(TIM1_BRK_TIM15_IRQn, 4, 0);
  HAL_NVIC_EnableIRQ(TIM1_BRK_TIM15_IRQn);
  /* TIM1_UP_TIM16_IRQn interrupt configuration */
  HAL_NVIC_SetPriority(TIM1_UP_TIM16_IRQn, 0, 0);
  HAL_NVIC_EnableIRQ(TIM1_UP_TIM16_IRQn);
  /* ADC1_2_IRQn interrupt configuration */
  HAL_NVIC_SetPriority(ADC1_2_IRQn, 2, 0);
  HAL_NVIC_EnableIRQ(ADC1_2_IRQn);
  /* TIM3_IRQn interrupt configuration */
  HAL_NVIC_SetPriority(TIM3_IRQn, 3, 0);
  HAL_NVIC_EnableIRQ(TIM3_IRQn);
}

static void MX_ADC1_Init(void)
{

  ADC_MultiModeTypeDef multimode = {0};
  ADC_InjectionConfTypeDef sConfigInjected = {0};
  ADC_ChannelConfTypeDef sConfig = {0};

  /** Common config
  */
  hadc1.Instance = ADC1;
  hadc1.Init.ClockPrescaler = ADC_CLOCK_ASYNC_DIV1;
  hadc1.Init.Resolution = ADC_RESOLUTION_12B;
  hadc1.Init.DataAlign = ADC_DATAALIGN_LEFT;
  hadc1.Init.GainCompensation = 0;
  hadc1.Init.ScanConvMode = ADC_SCAN_ENABLE;
  hadc1.Init.EOCSelection = ADC_EOC_SINGLE_CONV;
  hadc1.Init.LowPowerAutoWait = DISABLE;
  hadc1.Init.ContinuousConvMode = DISABLE;
  hadc1.Init.NbrOfConversion = 1;
  hadc1.Init.DiscontinuousConvMode = DISABLE;
  hadc1.Init.ExternalTrigConv = ADC_SOFTWARE_START;
  hadc1.Init.ExternalTrigConvEdge = ADC_EXTERNALTRIGCONVEDGE_NONE;
  hadc1.Init.DMAContinuousRequests = DISABLE;
  hadc1.Init.Overrun = ADC_OVR_DATA_PRESERVED;
  hadc1.Init.OversamplingMode = DISABLE;
  if (HAL_ADC_Init(&hadc1) != HAL_OK)
  {
    Error_Handler();
  }

  /** Configure the ADC multi-mode
  */
  multimode.Mode = ADC_MODE_INDEPENDENT;
  if (HAL_ADCEx_MultiModeConfigChannel(&hadc1, &multimode) != HAL_OK)
  {
    Error_Handler();
  }

  /** Configure Injected Channel
  */
  sConfigInjected.InjectedChannel = ADC_CHANNEL_15;
  sConfigInjected.InjectedRank = ADC_INJECTED_RANK_1;
  sConfigInjected.InjectedSamplingTime = ADC_SAMPLETIME_6CYCLES_5;
  sConfigInjected.InjectedSingleDiff = ADC_SINGLE_ENDED;
  sConfigInjected.InjectedOffsetNumber = ADC_OFFSET_NONE;
  sConfigInjected.InjectedOffset = 0;
  sConfigInjected.InjectedNbrOfConversion = 2;
  sConfigInjected.InjectedDiscontinuousConvMode = DISABLE;
  sConfigInjected.AutoInjectedConv = DISABLE;
  sConfigInjected.QueueInjectedContext = DISABLE;
  sConfigInjected.ExternalTrigInjecConv = ADC_EXTERNALTRIGINJEC_T1_TRGO;
  sConfigInjected.ExternalTrigInjecConvEdge = ADC_EXTERNALTRIGINJECCONV_EDGE_RISING;
  sConfigInjected.InjecOversamplingMode = DISABLE;
  if (HAL_ADCEx_InjectedConfigChannel(&hadc1, &sConfigInjected) != HAL_OK)
  {
    Error_Handler();
  }

  /** Configure Injected Channel
  */
  sConfigInjected.InjectedChannel = ADC_CHANNEL_2;
  sConfigInjected.InjectedRank = ADC_INJECTED_RANK_2;
  if (HAL_ADCEx_InjectedConfigChannel(&hadc1, &sConfigInjected) != HAL_OK)
  {
    Error_Handler();
  }

  /** Configure Regular Channel
  */
  sConfig.Channel = ADC_CHANNEL_1;
  sConfig.Rank = ADC_REGULAR_RANK_1;
  sConfig.SamplingTime = ADC_SAMPLETIME_47CYCLES_5;
  sConfig.SingleDiff = ADC_SINGLE_ENDED;
  sConfig.OffsetNumber = ADC_OFFSET_NONE;
  sConfig.Offset = 0;
  if (HAL_ADC_ConfigChannel(&hadc1, &sConfig) != HAL_OK)
  {
    Error_Handler();
  }

}

static void MX_ADC2_Init(void)
{

  ADC_InjectionConfTypeDef sConfigInjected = {0};

  /** Common config
  */
  hadc2.Instance = ADC2;
  hadc2.Init.ClockPrescaler = ADC_CLOCK_ASYNC_DIV1;
  hadc2.Init.Resolution = ADC_RESOLUTION_12B;
  hadc2.Init.DataAlign = ADC_DATAALIGN_LEFT;
  hadc2.Init.GainCompensation = 0;
  hadc2.Init.ScanConvMode = ADC_SCAN_ENABLE;
  hadc2.Init.EOCSelection = ADC_EOC_SINGLE_CONV;
  hadc2.Init.LowPowerAutoWait = DISABLE;
  hadc2.Init.ContinuousConvMode = DISABLE;
  hadc2.Init.NbrOfConversion = 1;
  hadc2.Init.DiscontinuousConvMode = DISABLE;
  hadc2.Init.DMAContinuousRequests = DISABLE;
  hadc2.Init.Overrun = ADC_OVR_DATA_PRESERVED;
  hadc2.Init.OversamplingMode = DISABLE;
  if (HAL_ADC_Init(&hadc2) != HAL_OK)
  {
    Error_Handler();
  }

  /** Configure Injected Channel
  */
  sConfigInjected.InjectedChannel = ADC_CHANNEL_2;
  sConfigInjected.InjectedRank = ADC_INJECTED_RANK_1;
  sConfigInjected.InjectedSamplingTime = ADC_SAMPLETIME_6CYCLES_5;
  sConfigInjected.InjectedSingleDiff = ADC_SINGLE_ENDED;
  sConfigInjected.InjectedOffsetNumber = ADC_OFFSET_NONE;
  sConfigInjected.InjectedOffset = 0;
  sConfigInjected.InjectedNbrOfConversion = 2;
  sConfigInjected.InjectedDiscontinuousConvMode = DISABLE;
  sConfigInjected.AutoInjectedConv = DISABLE;
  sConfigInjected.QueueInjectedContext = DISABLE;
  sConfigInjected.ExternalTrigInjecConv = ADC_EXTERNALTRIGINJEC_T1_TRGO;
  sConfigInjected.ExternalTrigInjecConvEdge = ADC_EXTERNALTRIGINJECCONV_EDGE_RISING;
  sConfigInjected.InjecOversamplingMode = DISABLE;
  if (HAL_ADCEx_InjectedConfigChannel(&hadc2, &sConfigInjected) != HAL_OK)
  {
    Error_Handler();
  }

  /** Configure Injected Channel
  */
  sConfigInjected.InjectedChannel = ADC_CHANNEL_12;
  sConfigInjected.InjectedRank = ADC_INJECTED_RANK_2;
  if (HAL_ADCEx_InjectedConfigChannel(&hadc2, &sConfigInjected) != HAL_OK)
  {
    Error_Handler();
  }

}

static void MX_CORDIC_Init(void)
{

  hcordic.Instance = CORDIC;
  if (HAL_CORDIC_Init(&hcordic) != HAL_OK)
  {
    Error_Handler();
  }

}

static void MX_SPI1_Init(void)
{

  /* SPI1 parameter configuration*/
  hspi1.Instance = SPI1;
  hspi1.Init.Mode = SPI_MODE_MASTER;
  hspi1.Init.Direction = SPI_DIRECTION_2LINES;
  hspi1.Init.DataSize = SPI_DATASIZE_16BIT;
  hspi1.Init.CLKPolarity = SPI_POLARITY_LOW;
  hspi1.Init.CLKPhase = SPI_PHASE_2EDGE;
  hspi1.Init.NSS = SPI_NSS_SOFT;
  hspi1.Init.BaudRatePrescaler = SPI_BAUDRATEPRESCALER_32;
  hspi1.Init.FirstBit = SPI_FIRSTBIT_MSB;
  hspi1.Init.TIMode = SPI_TIMODE_DISABLE;
  hspi1.Init.CRCCalculation = SPI_CRCCALCULATION_DISABLE;
  hspi1.Init.CRCPolynomial = 7;
  hspi1.Init.CRCLength = SPI_CRC_LENGTH_DATASIZE;
  hspi1.Init.NSSPMode = SPI_NSS_PULSE_DISABLE;
  if (HAL_SPI_Init(&hspi1) != HAL_OK)
  {
    Error_Handler();
  }

}

static void MX_TIM1_Init(void)
{

  TIM_MasterConfigTypeDef sMasterConfig = {0};
  TIM_OC_InitTypeDef sConfigOC = {0};
  TIM_BreakDeadTimeConfigTypeDef sBreakDeadTimeConfig = {0};

  htim1.Instance = TIM1;
  htim1.Init.Prescaler = ((TIM_CLOCK_DIVIDER) - 1);
  htim1.Init.CounterMode = TIM_COUNTERMODE_CENTERALIGNED1;
  htim1.Init.Period = ((PWM_PERIOD_CYCLES) / 2);
  htim1.Init.ClockDivision = TIM_CLOCKDIVISION_DIV2;
  htim1.Init.RepetitionCounter = (REP_COUNTER);
  htim1.Init.AutoReloadPreload = TIM_AUTORELOAD_PRELOAD_DISABLE;
  if (HAL_TIM_PWM_Init(&htim1) != HAL_OK)
  {
    Error_Handler();
  }
  sMasterConfig.MasterOutputTrigger = TIM_TRGO_OC4REF;
  sMasterConfig.MasterOutputTrigger2 = TIM_TRGO2_RESET;
  sMasterConfig.MasterSlaveMode = TIM_MASTERSLAVEMODE_DISABLE;
  if (HAL_TIMEx_MasterConfigSynchronization(&htim1, &sMasterConfig) != HAL_OK)
  {
    Error_Handler();
  }
  sConfigOC.OCMode = TIM_OCMODE_PWM1;
  sConfigOC.Pulse = ((PWM_PERIOD_CYCLES) / 4);
  sConfigOC.OCPolarity = TIM_OCPOLARITY_HIGH;
  sConfigOC.OCNPolarity = TIM_OCNPOLARITY_HIGH;
  sConfigOC.OCFastMode = TIM_OCFAST_DISABLE;
  sConfigOC.OCIdleState = TIM_OCIDLESTATE_RESET;
  sConfigOC.OCNIdleState = TIM_OCNIDLESTATE_RESET;
  if (HAL_TIM_PWM_ConfigChannel(&htim1, &sConfigOC, TIM_CHANNEL_1) != HAL_OK)
  {
    Error_Handler();
  }
  if (HAL_TIM_PWM_ConfigChannel(&htim1, &sConfigOC, TIM_CHANNEL_2) != HAL_OK)
  {
    Error_Handler();
  }
  if (HAL_TIM_PWM_ConfigChannel(&htim1, &sConfigOC, TIM_CHANNEL_3) != HAL_OK)
  {
    Error_Handler();
  }
  sConfigOC.OCMode = TIM_OCMODE_PWM2;
  sConfigOC.Pulse = (((PWM_PERIOD_CYCLES) / 2) - (HTMIN));
  if (HAL_TIM_PWM_ConfigChannel(&htim1, &sConfigOC, TIM_CHANNEL_4) != HAL_OK)
  {
    Error_Handler();
  }
  sBreakDeadTimeConfig.OffStateRunMode = TIM_OSSR_ENABLE;
  sBreakDeadTimeConfig.OffStateIDLEMode = TIM_OSSI_ENABLE;
  sBreakDeadTimeConfig.LockLevel = TIM_LOCKLEVEL_OFF;
  sBreakDeadTimeConfig.DeadTime = ((DEAD_TIME_COUNTS) / 2);
  sBreakDeadTimeConfig.BreakState = TIM_BREAK_DISABLE;
  sBreakDeadTimeConfig.BreakPolarity = TIM_BREAKPOLARITY_HIGH;
  sBreakDeadTimeConfig.BreakFilter = 0;
  sBreakDeadTimeConfig.BreakAFMode = TIM_BREAK_AFMODE_INPUT;
  sBreakDeadTimeConfig.Break2State = TIM_BREAK2_DISABLE;
  sBreakDeadTimeConfig.Break2Polarity = TIM_BREAK2POLARITY_HIGH;
  sBreakDeadTimeConfig.Break2Filter = 3;
  sBreakDeadTimeConfig.Break2AFMode = TIM_BREAK_AFMODE_INPUT;
  sBreakDeadTimeConfig.AutomaticOutput = TIM_AUTOMATICOUTPUT_DISABLE;
  if (HAL_TIMEx_ConfigBreakDeadTime(&htim1, &sBreakDeadTimeConfig) != HAL_OK)
  {
    Error_Handler();
  }
  HAL_TIM_MspPostInit(&htim1);

}

static void MX_TIM3_Init(void)
{

  TIM_Encoder_InitTypeDef sConfig = {0};
  TIM_MasterConfigTypeDef sMasterConfig = {0};

  htim3.Instance = TIM3;
  htim3.Init.Prescaler = 0;
  htim3.Init.CounterMode = TIM_COUNTERMODE_UP;
  htim3.Init.Period = M1_PULSE_NBR;
  htim3.Init.ClockDivision = TIM_CLOCKDIVISION_DIV1;
  htim3.Init.AutoReloadPreload = TIM_AUTORELOAD_PRELOAD_DISABLE;
  sConfig.EncoderMode = TIM_ENCODERMODE_TI12;
  sConfig.IC1Polarity = TIM_ICPOLARITY_RISING;
  sConfig.IC1Selection = TIM_ICSELECTION_DIRECTTI;
  sConfig.IC1Prescaler = TIM_ICPSC_DIV1;
  sConfig.IC1Filter = M1_ENC_IC_FILTER;
  sConfig.IC2Polarity = TIM_ICPOLARITY_RISING;
  sConfig.IC2Selection = TIM_ICSELECTION_DIRECTTI;
  sConfig.IC2Prescaler = TIM_ICPSC_DIV1;
  sConfig.IC2Filter = M1_ENC_IC_FILTER;
  if (HAL_TIM_Encoder_Init(&htim3, &sConfig) != HAL_OK)
  {
    Error_Handler();
  }
  sMasterConfig.MasterOutputTrigger = TIM_TRGO_RESET;
  sMasterConfig.MasterSlaveMode = TIM_MASTERSLAVEMODE_DISABLE;
  if (HAL_TIMEx_MasterConfigSynchronization(&htim3, &sMasterConfig) != HAL_OK)
  {
    Error_Handler();
  }

}

static void MX_USART2_UART_Init(void)
{

  huart2.Instance = USART2;
  huart2.Init.BaudRate = 115200;
  huart2.Init.WordLength = UART_WORDLENGTH_8B;
  huart2.Init.StopBits = UART_STOPBITS_1;
  huart2.Init.Parity = UART_PARITY_NONE;
  huart2.Init.Mode = UART_MODE_TX_RX;
  huart2.Init.HwFlowCtl = UART_HWCONTROL_NONE;
  huart2.Init.OverSampling = UART_OVERSAMPLING_16;
  huart2.Init.OneBitSampling = UART_ONE_BIT_SAMPLE_DISABLE;
  huart2.Init.ClockPrescaler = UART_PRESCALER_DIV1;
  huart2.AdvancedInit.AdvFeatureInit = UART_ADVFEATURE_NO_INIT;
  if (HAL_UART_Init(&huart2) != HAL_OK)
  {
    Error_Handler();
  }
  if (HAL_UARTEx_SetTxFifoThreshold(&huart2, UART_TXFIFO_THRESHOLD_1_8) != HAL_OK)
  {
    Error_Handler();
  }
  if (HAL_UARTEx_SetRxFifoThreshold(&huart2, UART_RXFIFO_THRESHOLD_1_8) != HAL_OK)
  {
    Error_Handler();
  }
  if (HAL_UARTEx_DisableFifoMode(&huart2) != HAL_OK)
  {
    Error_Handler();
  }

}

static void MX_GPIO_Init(void)
{
  GPIO_InitTypeDef GPIO_InitStruct = {0};

  /* GPIO Ports Clock Enable */
  __HAL_RCC_GPIOF_CLK_ENABLE();
  __HAL_RCC_GPIOA_CLK_ENABLE();
  __HAL_RCC_GPIOB_CLK_ENABLE();

  /*Configure GPIO pin Output Level */
  HAL_GPIO_WritePin(GPIOA, GPIO_PIN_4, GPIO_PIN_SET);

  /*Configure GPIO pin Output Level */
  HAL_GPIO_WritePin(GPIOB, GPIO_PIN_11|GPIO_PIN_9, GPIO_PIN_RESET);

  /*Configure GPIO pin Output Level */
  HAL_GPIO_WritePin(M1_EN_DRIVER_GPIO_Port, M1_EN_DRIVER_Pin, GPIO_PIN_SET);

  /*Configure GPIO pin Output Level */
  HAL_GPIO_WritePin(GPIOA, GPIO_PIN_15, GPIO_PIN_RESET);

  /*Configure GPIO pins : PA4 PA15 */
  GPIO_InitStruct.Pin = GPIO_PIN_4|GPIO_PIN_15;
  GPIO_InitStruct.Mode = GPIO_MODE_OUTPUT_PP;
  GPIO_InitStruct.Pull = GPIO_NOPULL;
  GPIO_InitStruct.Speed = GPIO_SPEED_FREQ_LOW;
  HAL_GPIO_Init(GPIOA, &GPIO_InitStruct);

  /*Configure GPIO pins : PB10 PB6 PB8 */
  GPIO_InitStruct.Pin = GPIO_PIN_10|GPIO_PIN_6|GPIO_PIN_8;
  GPIO_InitStruct.Mode = GPIO_MODE_INPUT;
  GPIO_InitStruct.Pull = GPIO_NOPULL;
  HAL_GPIO_Init(GPIOB, &GPIO_InitStruct);

  /*Configure GPIO pins : PB11 PB9 */
  GPIO_InitStruct.Pin = GPIO_PIN_11|GPIO_PIN_9;
  GPIO_InitStruct.Mode = GPIO_MODE_OUTPUT_PP;
  GPIO_InitStruct.Pull = GPIO_NOPULL;
  GPIO_InitStruct.Speed = GPIO_SPEED_FREQ_LOW;
  HAL_GPIO_Init(GPIOB, &GPIO_InitStruct);

  /*Configure GPIO pin : M1_EN_DRIVER_Pin */
  GPIO_InitStruct.Pin = M1_EN_DRIVER_Pin;
  GPIO_InitStruct.Mode = GPIO_MODE_OUTPUT_PP;
  GPIO_InitStruct.Pull = GPIO_PULLUP;
  GPIO_InitStruct.Speed = GPIO_SPEED_FREQ_LOW;
  HAL_GPIO_Init(M1_EN_DRIVER_GPIO_Port, &GPIO_InitStruct);

}

/* USER CODE BEGIN 4 */

/* ===== ESP32 link on USART2 (PA2 TX / PA3 RX). The USB-CDC debug console is a
   separate peripheral, so both run at once. See esp_link.c + protocol/. ======= */

/* Non-blocking TX ring: the app thread (sole producer) fills head; the USART2
   TXE interrupt (sole consumer) drains tail. Single-producer/single-consumer =>
   lock-free. Keeps a slow TX from ever busy-waiting in a task or an ISR. */
#define ESP_TX_RING 512u
static volatile uint8_t  esp_tx_buf[ESP_TX_RING];
static volatile uint16_t esp_tx_head = 0u, esp_tx_tail = 0u;

/* Writer bound into esp_link: enqueue a byte and make sure TX interrupts run. */
static void esp_uart_write_byte(uint8_t b)
{
  uint16_t next = (uint16_t)((esp_tx_head + 1u) % ESP_TX_RING);
  if (next == esp_tx_tail) { return; }                     /* ring full -> drop (CRC catches) */
  esp_tx_buf[esp_tx_head] = b;
  esp_tx_head = next;
  SET_BIT(USART2->CR1, USART_CR1_TXEIE_TXFNFIE);           /* ensure TXE interrupt is on */
}

/* USART2 interrupt: RX byte -> link parser (reading RDR clears RXNE; clear error
   flags so an overrun can't wedge RX); TXE -> pop the TX ring. */
void USART2_IRQHandler(void)
{
  uint32_t isr = USART2->ISR;
  if ((isr & (USART_ISR_ORE | USART_ISR_FE | USART_ISR_NE)) != 0U)
  {
    USART2->ICR = USART_ICR_ORECF | USART_ICR_FECF | USART_ICR_NECF;
  }
  if ((isr & USART_ISR_RXNE_RXFNE) != 0U)
  {
    esp_link_feed((uint8_t)(USART2->RDR & 0xFFU));
  }
  if (((isr & USART_ISR_TXE_TXFNF) != 0U) && ((USART2->CR1 & USART_CR1_TXEIE_TXFNFIE) != 0U))
  {
    if (esp_tx_tail != esp_tx_head)
    {
      USART2->TDR = (uint16_t)esp_tx_buf[esp_tx_tail];
      esp_tx_tail = (uint16_t)((esp_tx_tail + 1u) % ESP_TX_RING);
    }
    else
    {
      CLEAR_BIT(USART2->CR1, USART_CR1_TXEIE_TXFNFIE);      /* ring empty -> stop TX ints */
    }
  }
}

/* Fill the fast telemetry status from the live motor state. */
static void esp_build_status(tsl_status_t *s)
{
  extern volatile float g_enc_speed_rpm;
  s->speed_rpm   = (int16_t)g_enc_speed_rpm;
  s->torque_mA   = (int16_t)((float)FOCVars[M1].Iqd.q * 1000.0f / (float)CURRENT_CONV_FACTOR);
  s->id_mA       = (int16_t)((float)FOCVars[M1].Iqd.d * 1000.0f / (float)CURRENT_CONV_FACTOR);
  s->vbus_mV     = (uint16_t)(VBS_GetAvBusVoltage_V(&BusVoltageSensor_M1._Super) * 1000u);
  s->temp_c_x10  = (int16_t)((int32_t)NTC_GetAvTemp_C(&TempSensor_M1) * 10);
  s->fault_flags = (uint16_t)MC_GetOccurredFaultsMotor1();/* raw MCSDK code for now; map later    */
  switch (MC_GetSTMStateMotor1())
  {
    case RUN:        s->state = (uint8_t)TSL_STATE_RUN;   break;
    case IDLE:       s->state = (uint8_t)TSL_STATE_IDLE;  break;
    case ALIGNMENT:  s->state = (uint8_t)TSL_STATE_ALIGN; break;
    case FAULT_NOW:
    case FAULT_OVER: s->state = (uint8_t)TSL_STATE_FAULT; break;
    default:         s->state = (uint8_t)TSL_STATE_STOP;  break;
  }
  s->flags = 0u;
  {
    static uint8_t  s_boot_ready = 0u;          /* latches on first RUN (alignment done) */
    extern volatile uint8_t g_cogg_enable;      /* anti-cogging FF active     */
    extern volatile uint8_t g_cogg_cal_state;   /* 0 idle, 1 sweep, 5 probe   */
    extern volatile int32_t g_pos_counts;       /* multi-turn count, updated every MF tick */
    if (s->state == (uint8_t)TSL_STATE_RUN) { s_boot_ready = 1u; }  /* boot+align complete */
    if (s_boot_ready != 0u)     { s->flags |= (uint8_t)TSL_SFLAG_READY; }
    if (g_cogg_enable != 0u)    { s->flags |= (uint8_t)TSL_SFLAG_COGGING_ON; }
    if (g_cogg_cal_state != 0u) { s->flags |= (uint8_t)TSL_SFLAG_CALIBRATING; }
    s->position = g_pos_counts;
  }
}

/* ESP-link service, called from the ~1 kHz MF hook. This is the SOLE origin of
   ESP-link TX (single-producer for the lock-free TX ring): reliable ACK/retransmit
   every tick, telemetry at 250 Hz, and the link watchdog. Read-only MC/telemetry
   getters only -- no MC_Start/Stop here (those are serviced in appTask). */
void Ropetow_EspLinkService(void)
{
  static uint8_t div = 0u;
  uint32_t now = HAL_GetTick();
  esp_link_reliable_tick(now);
  if (++div >= 4u)                                /* 1 kHz / 4 = 250 Hz telemetry + watchdog
                                                     (~6.5 kB/s of 11.5 kB/s @115200 -> safe;
                                                     500 Hz/1 kHz would need a baud bump BOTH sides) */
  {
    div = 0u;
    tsl_status_t st;
    esp_build_status(&st);
    esp_link_send_status(&st);
    if ((esp_link_rx_frames() > 0U) && (esp_link_ok(now) == 0U))
    {
      extern volatile int32_t g_torque_set_ma; extern volatile uint8_t g_torque_set_req;
      g_torque_set_ma = 0; g_torque_set_req = 1U;  /* link lost -> safe: command 0 torque */
    }
  }

  /* Live torque-current setpoint -- applied EVERY MF tick (~1 kHz) so an ESP-side
     PID (or the CDC 't') actuates with ~1 ms latency instead of the old 10 Hz
     app-task rate. Both 't<mA>' and the heartbeat set g_torque_set_req; the
     link-lost watchdog above sets 0. Zero ramp = immediate; the outer loop and the
     current loop provide the smoothing. Fires only on a NEW setpoint (req cleared
     after apply), so at most the heartbeat rate, not every tick. No LOG here: it
     would flood at up to 1 kHz and race the log ring. */
  {
    extern volatile int32_t g_torque_set_ma;
    extern volatile uint8_t g_torque_set_req;
    if ((g_torque_set_req != 0U) && (MC_GetSTMStateMotor1() == RUN))
    {
      int32_t ma = g_torque_set_ma;
      g_torque_set_req = 0U;
      if (ma >  29000) { ma =  29000; }
      if (ma < -29000) { ma = -29000; }
      MC_ProgramTorqueRampMotor1_F((float)ma / 1000.0f, 0U);   /* 0 ms = immediate */
    }
  }
}

/* --- Encoder index (Z) on PB3 ---------------------------------------------
 * The AS5047 index pulses once per MECHANICAL revolution. EMI miscounts on the
 * ABI lines accumulate in TIM3->CNT and drift the commutation angle; this snaps
 * the count back to its index-aligned value every rev. EXTI3 rising edge, NVIC
 * priority below the FOC ISRs. The first index after each RUN captures the
 * reference count (consistent with the startup alignment); later indexes correct
 * only plausible drift (<~1/32 rev) so a spurious edge can't throw the angle. */
static void Ropetow_IndexInit(void)
{
  GPIO_InitTypeDef gi = {0};
  __HAL_RCC_GPIOB_CLK_ENABLE();
  gi.Pin  = GPIO_PIN_3;
  gi.Mode = GPIO_MODE_IT_RISING;          /* index idles low, pulses high */
  gi.Pull = GPIO_PULLDOWN;
  HAL_GPIO_Init(GPIOB, &gi);
  HAL_NVIC_SetPriority(EXTI3_IRQn, 5, 0); /* below TIM1/ADC/TIM3/BRK (prio 0..4) */
  HAL_NVIC_EnableIRQ(EXTI3_IRQn);
}

void EXTI3_IRQHandler(void)
{
  if (__HAL_GPIO_EXTI_GET_IT(GPIO_PIN_3) != 0U)
  {
    __HAL_GPIO_EXTI_CLEAR_IT(GPIO_PIN_3);
    if (MC_GetSTMStateMotor1() == RUN)
    {
      uint16_t cnt = (uint16_t)TIM3->CNT;
      if (g_idx_have == 0U)
      {
        g_idx_cnt  = cnt;                 /* first index this run = reference */
        g_idx_have = 1U;
      }
      else
      {
        int32_t period = (int32_t)M1_PULSE_NBR + 1;       /* TIM3 wraps 0..M1_PULSE_NBR */
        int32_t d = (int32_t)cnt - (int32_t)g_idx_cnt;    /* shortest signed wrap diff  */
        if (d >  (period / 2)) { d -= period; }
        if (d < -(period / 2)) { d += period; }
        if ((d > -128) && (d < 128))      /* correct small drift; reject spurious edges */
        {
          TIM3->CNT = (uint32_t)g_idx_cnt;
        }
      }
      g_idx_events++;
    }
  }
}

static const char *mc_state_name(MCI_State_t state)
{
  switch (state)
  {
    case IDLE:            return "IDLE";
    case ICLWAIT:         return "ICLWAIT";
    case ALIGNMENT:       return "ALIGNMENT";
    case CHARGE_BOOT_CAP: return "CHARGE_BOOT_CAP";
    case OFFSET_CALIB:    return "OFFSET_CALIB";
    case START:           return "START";
    case SWITCH_OVER:     return "SWITCH_OVER";
    case RUN:             return "RUN";
    case STOP:            return "STOP";
    case FAULT_NOW:       return "FAULT_NOW";
    case FAULT_OVER:      return "FAULT_OVER";
    case WAIT_STOP_MOTOR: return "WAIT_STOP_MOTOR";
    default:              return "UNKNOWN";
  }
}

static void log_mc_faults(const char *label, uint16_t faults)
{
  LOG_Printf("[motor]   %s=0x%04X%s%s%s%s%s%s%s%s%s\r\n", label, (unsigned)faults,
             (faults & MC_DURATION)   ? " FOC_DURATION" : "",
             (faults & MC_OVER_VOLT)  ? " OVER_VOLT"    : "",
             (faults & MC_UNDER_VOLT) ? " UNDER_VOLT"   : "",
             (faults & MC_OVER_TEMP)  ? " OVER_TEMP"    : "",
             (faults & MC_START_UP)   ? " START_UP"     : "",
             (faults & MC_SPEED_FDBK) ? " SPEED_FDBK"   : "",
             (faults & MC_OVER_CURR)  ? " OVER_CURR"    : "",
             (faults & MC_SW_ERROR)   ? " SW_ERROR"     : "",
             (faults & MC_DP_FAULT)   ? " DP_FAULT"     : "");
}

/* Periodic motor status over USB CDC: one line per MOTOR_LOG_PERIOD_MS, plus
   an immediate line whenever the MC state or the fault flags change. Called
   from the low-priority app task; LOG_Printf only fills the ring buffer, so
   nothing here blocks or disturbs the FOC interrupts. */
static void motor_status_log(void)
{
  static uint32_t    last_tick;
  static MCI_State_t last_state  = STATE_ENUM_COUNT;   /* forces first print */
  static uint16_t    last_faults;

  MCI_State_t state   = MC_GetSTMStateMotor1();
  uint16_t    faults  = MC_GetCurrentFaultsMotor1();
  uint32_t    now     = HAL_GetTick();
  uint8_t     changed = (state != last_state) || (faults != last_faults);

  if (!changed && ((now - last_tick) < MOTOR_LOG_PERIOD_MS))
  {
    return;
  }
  last_tick   = now;
  last_state  = state;
  last_faults = faults;

  /* newlib-nano printf has no %f support, so format the current with integer
     math: round to tenths of an amp, then split into whole/fractional digit. */
  int32_t i_tenths = (int32_t)(((float)MC_GetPhaseCurrentAmplitudeMotor1() *
                                (float)CURRENT_CONV_FACTOR_INV) * 10.0f + 0.5f);

  /* Single-line telemetry: only values that CHANGE, no static config.
       spd    mech speed (MCSDK avg -- what the governor/fault use), rpm
       cap    effective speed cap (ESP/CDC request, hard-clamped), rpm
       brk    governor braking actually applied, mA
       Iqref  q-axis current reference / Iq,Id MEASURED dq currents (s16A)
       IdFW   flux-weakening d reference (s16A, 0 = FW idle)
       avV    filtered |Vqd| vs FW engage target, counts
       I,Vb   phase current amplitude (A), bus voltage (V)
       enc    TIM3 speed-sensor reliability;  err  SPI encoder read failures */
  {
    extern volatile float    g_spdcap_rpm;
    extern volatile float    g_spdcap_brake_now_a;
    extern volatile float    g_spdcap_hard_rpm, g_spdcap_band_rpm;
    extern volatile float    g_spdcap_brake_start_rpm, g_spdcap_brake_max_a;
    extern volatile uint32_t g_spi_err_count;
    extern int16_t Ropetow_McFwAvVolt(void);
    extern int16_t Ropetow_McFwVTarget(void);
    LOG_Printf("[m] %s spd=%ld cap=%d brk=%d gov=%d/%d/%d/%d | Iqref=%d Iq=%d Id=%d IdFW=%d | "
               "avV=%d/%d | I=%ld.%ldA Vb=%uV enc=%s err=%lu\r\n",
               mc_state_name(state),
               (int32_t)MC_GetMecSpeedAverageMotor1() * U_RPM / SPEED_UNIT,
               (int)g_spdcap_rpm,
               (int)(g_spdcap_brake_now_a * 1000.0f),
               (int)g_spdcap_hard_rpm, (int)g_spdcap_band_rpm,
               (int)g_spdcap_brake_start_rpm, (int)(g_spdcap_brake_max_a * 1000.0f),
               (int)FOCVars[M1].Iqdref.q,
               (int)FOCVars[M1].Iqd.q,
               (int)FOCVars[M1].Iqd.d,
               (int)FOCVars[M1].Iqdref.d,
               (int)Ropetow_McFwAvVolt(), (int)Ropetow_McFwVTarget(),
               i_tenths / 10, i_tenths % 10,
               (unsigned)VBS_GetAvBusVoltage_V(&BusVoltageSensor_M1._Super),
               MC_GetSpeedSensorReliabilityMotor1() ? "ok" : "BAD",
               (unsigned long)g_spi_err_count);
  }

  if (changed && ((faults != 0U) || (MC_GetOccurredFaultsMotor1() != 0U)))
  {
    log_mc_faults("current", faults);
    log_mc_faults("occurred", MC_GetOccurredFaultsMotor1());
  }
}

/* Application thread. Runs after the scheduler starts (and after the medium-
   frequency task). The DRV8353 must be configured (6x PWM, CSA gain 20 V/V,
   OCP) BEFORE the motor starts, i.e. before any PWM. */
static void StartAppTask(void const *argument)
{
  (void)argument;

  /* Bring up USB CDC here. CubeMX places MX_USB_Device_Init() in the *weak*
     startMediumFrequencyTask in main.c, but the MCSDK provides a strong
     startMediumFrequencyTask in mc_tasks.c that OVERRIDES it -- so that init
     never runs and no CDC device enumerates. Call it from this task instead. */
  MX_USB_Device_Init();

  /* Let USB CDC enumerate and the supply settle before talking to anything. */
  osDelay(1000);
  LOG_Init();

  /* ESP32 link: bind esp_link to USART2 (already MX-init'd) + enable RX interrupt.
     Priority 6 -> below the FOC/ADC/encoder ISRs (0..4), so it never preempts control. */
  esp_link_init(esp_uart_write_byte);
  SET_BIT(USART2->CR1, USART_CR1_RXNEIE_RXFNEIE);
  HAL_NVIC_SetPriority(USART2_IRQn, 6, 0);
  HAL_NVIC_EnableIRQ(USART2_IRQn);

  DRV8353_Status drv = DRV8353_Init();

  LOG_Printf("\r\n=== Trainsonic boot ===\r\n");
  LOG_Printf("DRV8353_Init=%d\r\n", (int)drv);
  DRV8353_LogStatus();
  {
    AS5047_Status enc = AS5047_Init(&hspi1);   /* FOC now commutates on the AS5047 SPI angle */
    LOG_Printf("AS5047_Init=%d\r\n", (int)enc);
    AS5047_LogStatus(&hspi1);                  /* dump AGC/MAGL/MAGH -> magnet health vs vibration */
  }
  LOG_Printf("=== end boot diagnostics ===\r\n");

  /* --- Automatic motor start --------------------------------------------
   * WARNING: spins the drive on every power-up with no operator interlock.
   * On a rope-tow that moves a load this is a hazard -- add an enable / e-stop
   * interlock before field use. Only start if the gate driver configured. */
  if ((drv == DRV8353_OK) && (ENC_ONLY == 0))
  {
    Ropetow_IndexInit();                     /* arm PB3 index -> TIM3 count reset */
    (void)MC_AcknowledgeFaultMotor1();       /* clear any latched fault        */
#if BOOT_OPENLOOP
    {
      /* Open-loop forced commutation (method A INL capture): encoder out of the
         loop, torque mode + fixed Iq, electrical field rotated at a constant
         commanded speed. After MCSDK alignment locks the rotor, the forced ramp
         carries it around at BOOT_OL_SPEED_RPM. */
      extern volatile uint8_t g_use_spi_commutation;
      extern volatile uint8_t g_ol_enable;
      extern volatile float   g_ol_step;
      g_use_spi_commutation = 0U;            /* don't extrapolate the encoder      */
      g_ol_step = (float)BOOT_OL_SPEED_RPM * (float)POLE_PAIR_NUM * 65536.0f
                  / (60.0f * (float)ISR_FREQUENCY_HZ);
      g_ol_enable = 1U;
      MC_ProgramTorqueRampMotor1_F(BOOT_OL_IQ_A, BOOT_TORQUE_RAMP_MS);
      if (MC_StartMotor1())
      {
        LOG_Printf("OPEN-LOOP start: forced %d rpm, Iq=%d mA (encoder out of loop)\r\n",
                   (int)BOOT_OL_SPEED_RPM, (int)(BOOT_OL_IQ_A * 1000.0f));
      }
      else
      {
        LOG_Printf("Motor start REJECTED: state=%d faults=0x%04X\r\n",
                   (int)MC_GetSTMStateMotor1(),
                   (unsigned)MC_GetCurrentFaultsMotor1());
      }
    }
#elif (STEP_MODE == 1) || (STEP_MODE == 2)
    /* Closed-loop SPEED mode. Mode 1: baseline for the speed-step test.
       Mode 2: hold a constant speed for the Iq-ripple capture. */
  #if STEP_MODE == 2
    #define BOOT_SPD_RPM RIPPLE_SPEED_RPM
  #else
    #define BOOT_SPD_RPM SPEED_BASE_RPM
  #endif
    MC_ProgramSpeedRampMotor1((int16_t)((int32_t)BOOT_SPD_RPM * SPEED_UNIT / U_RPM),
                              BOOT_SPEED_RAMP_MS);
    if (MC_StartMotor1())
    {
      LOG_Printf("Motor start commanded -> speed mode, %d rpm over %d ms\r\n",
                 (int)BOOT_SPD_RPM, BOOT_SPEED_RAMP_MS);
    }
    else
    {
      LOG_Printf("Motor start REJECTED: state=%d faults=0x%04X\r\n",
                 (int)MC_GetSTMStateMotor1(),
                 (unsigned)MC_GetCurrentFaultsMotor1());
    }
#else
    /* Closed-loop TORQUE mode: encoder commutation (g_use_spi_commutation=1),
       no speed regulation -- Iq ramps to BOOT_TORQUE_REF_A and the motor produces
       that torque (unloaded it accelerates until friction/back-EMF balance). */
    MC_ProgramTorqueRampMotor1_F(BOOT_TORQUE_REF_A, BOOT_TORQUE_RAMP_MS);
    if (MC_StartMotor1())
    {
      LOG_Printf("Motor start commanded -> torque mode, Iq=%d mA over %d ms\r\n",
                 (int)(BOOT_TORQUE_REF_A * 1000.0f), BOOT_TORQUE_RAMP_MS);
    }
    else
    {
      LOG_Printf("Motor start REJECTED: state=%d faults=0x%04X\r\n",
                 (int)MC_GetSTMStateMotor1(),
                 (unsigned)MC_GetCurrentFaultsMotor1());
    }
#endif
  }
  else if (ENC_ONLY != 0)
  {
    LOG_Printf("ENC_ONLY: motor NOT started -- streaming raw encoder. Turn shaft by hand.\r\n");
  }
  else
  {
    LOG_Printf("Motor start SKIPPED: DRV8353_Init=%d\r\n", (int)drv);
  }

  for (;;)
  {
    static uint32_t run_ticks = 0U;
    extern uint16_t          g_cal_raw[];
    extern volatile uint16_t g_cal_idx;
    extern volatile uint8_t  g_cal_state;
    extern int16_t           g_step_ref[];
    extern int16_t           g_step_iq[];
    extern volatile uint16_t g_step_idx;
    extern volatile uint8_t  g_step_state;
    extern volatile uint8_t  g_step_request;
    extern volatile uint8_t  g_inj_override;
    extern volatile int16_t  g_inj_s16;
    extern volatile uint8_t  g_step_axis;
    extern volatile uint8_t  g_step_mode;
    extern volatile uint16_t g_cap_decim;

#if ENC_ONLY
    /* Pure encoder readout: the motor was never started, so the MF hook isn't
       touching the SPI and appTask owns it. Stream the raw AS5047 reading (~10 Hz)
       so the encoder/magnet can be validated in isolation. Watch raw sweep
       0..16383 smoothly per hand-turn, AGC mid-scale, all flags 0. */
    AS5047_LogAngle(&hspi1);
    for (uint16_t eguard = 0U; (LOG_Pending() > 0U) && (eguard < 200U); eguard++)
    { LOG_Process(); osDelay(2U); }
    osDelay(80U);
    continue;
#endif

    /* One-shot: log the calibrated 3-shunt offsets once the motor is running.
       A phase offset that differs from the others is a DC current bias -> the
       1x-electrical Iq ripple we saw. ODrive re-nulls these every startup. */
    {
      static uint8_t offsets_logged = 0U;
      extern void Ropetow_GetOffsets(int32_t *a, int32_t *b, int32_t *c);
      if ((offsets_logged == 0U) && (MC_GetSTMStateMotor1() == RUN))
      {
        int32_t oa = 0, ob = 0, oc = 0;
        Ropetow_GetOffsets(&oa, &ob, &oc);
        LOG_Printf("offsets(3-shunt): A=%ld B=%ld C=%ld  spread=%ld\r\n",
                   (long)oa, (long)ob, (long)oc,
                   (long)((oa>ob?oa:ob)>oc ? (oa>ob?oa:ob) : oc) -
                   (long)((oa<ob?oa:ob)<oc ? (oa<ob?oa:ob) : oc));
        offsets_logged = 1U;
      }
    }

    /* Live torque-current setpoint ('t<mA>' / ESP heartbeat) is now applied in
       Ropetow_EspLinkService() at ~1 kHz (0 ms ramp) instead of here at 10 Hz --
       moved so an ESP-side PID actuates with ~1 ms latency. See that function.
       (The old console "torque set -> N mA" confirmation was dropped to avoid
       flooding the log at up to 1 kHz; ask if you want a throttled version.) */

    /* Live SPEED setpoint ('s<rpm>'): command a speed ramp (switches to / stays in
       speed control). Clamped to a safe 0..600 rpm. Sweep this to find where the
       low-speed stick-slip starts/stops. */
    {
      extern volatile int32_t g_speed_set_rpm;
      extern volatile uint8_t g_speed_set_req;
      if ((g_speed_set_req != 0U) && (MC_GetSTMStateMotor1() == RUN))
      {
        int32_t rpm = g_speed_set_rpm;
        g_speed_set_req = 0U;
        if (rpm > 500) { rpm = 500; }
        if (rpm < 0)   { rpm = 0; }
        MC_ProgramSpeedRampMotor1((int16_t)((int32_t)rpm * SPEED_UNIT / U_RPM), 500U);
        LOG_Printf("speed set -> %ld rpm\r\n", (long)rpm);
      }
    }

    /* Motor restart ('R'): acknowledge any latched fault and re-start the drive in
       torque mode at 0 A (stationary, safe) so it lands in RUN -- e.g. after a
       speed-feedback fault, or to re-arm for the 'j' / position workflows without
       a board reset. Mirrors the boot start sequence; logs the same way. NOTE: if
       the underlying fault (e.g. enc=BAD speed reliability) persists, the drive
       will simply re-fault -- fix the root cause, this only clears the latch. */
    {
      extern volatile uint8_t g_restart_req;
      if (g_restart_req != 0U)
      {
        g_restart_req = 0U;
        (void)MC_AcknowledgeFaultMotor1();
        MC_ProgramTorqueRampMotor1_F(0.0f, 0U);
        if (MC_StartMotor1())
        {
          LOG_Printf("restart: motor commanded -> torque mode, 0 A\r\n");
        }
        else
        {
          LOG_Printf("restart REJECTED: state=%d faults=0x%04X\r\n",
                     (int)MC_GetSTMStateMotor1(),
                     (unsigned)MC_GetCurrentFaultsMotor1());
        }
      }
    }

    /* ESP32 link commands (mode / enable / e-stop): the RX ISR set these request
       flags; service them here in thread context where the MC API is safe. */
    {
      extern volatile uint8_t g_esp_estop_req, g_esp_enable_req, g_esp_enable_val;
      extern volatile uint8_t g_esp_mode_req,  g_esp_mode_val;
      if (g_esp_estop_req != 0U)
      {
        g_esp_estop_req = 0U;
        MC_StopMotor1();                                   /* hard safe stop (FETs off) */
        LOG_Printf("[esp] ESTOP -> motor stopped\r\n");
      }
      if (g_esp_enable_req != 0U)
      {
        uint8_t en = g_esp_enable_val; g_esp_enable_req = 0U;
        if (en != 0U)
        {
          if (MC_GetSTMStateMotor1() != RUN)
          {
            (void)MC_AcknowledgeFaultMotor1();
            MC_ProgramTorqueRampMotor1_F(0.0f, 0U);
            (void)MC_StartMotor1();
          }
          LOG_Printf("[esp] ENABLE -> run\r\n");
        }
        else
        {
          MC_StopMotor1();
          LOG_Printf("[esp] DISABLE -> stop\r\n");
        }
      }
      if (g_esp_mode_req != 0U)
      {
        uint8_t mode = g_esp_mode_val; g_esp_mode_req = 0U;
        if (MC_GetSTMStateMotor1() == RUN)
        {
          if (mode == (uint8_t)TSL_MODE_SPEED)       { MC_ProgramSpeedRampMotor1(0, 500U); }
          else if (mode == (uint8_t)TSL_MODE_TORQUE) { MC_ProgramTorqueRampMotor1_F(0.0f, 200U); }
          else                                       { MC_ProgramTorqueRampMotor1_F(0.0f, 0U); } /* IDLE */
        }
        LOG_Printf("[esp] mode -> %u\r\n", (unsigned)mode);
      }
    }

    /* Raw per-phase current log ('j<rpm>'): burst the measured phase currents
       (Ia, Ib, Ic = -(Ia+Ib)) to characterise the 3-shunt sense chain.
         j0      -> standstill, zero current commanded: residual DC = offset error,
                    spread = noise (currents should sit at ~0).
         j<rpm>  -> spin at a constant speed first, then sample: currents are AC
                    (mean ~0, pkpk = current amplitude), then the motor is stopped.
       Values are MCSDK s16 current units (offset already removed; the calibrated
       offsets are printed too so raw ADC can be reconstructed). */
    {
      extern volatile uint8_t g_iadc_log_req;
      extern volatile uint8_t g_pos_mode;
      extern void Ropetow_GetOffsets(int32_t *a, int32_t *b, int32_t *c);
      if (g_iadc_log_req != 0U)
      {
        g_iadc_log_req = 0U;
        if (MC_GetSTMStateMotor1() != RUN)
        {
          LOG_Printf("iadc: SKIPPED -- drive not in RUN (state=%d)\r\n",
                     (int)MC_GetSTMStateMotor1());
        }
        else if (g_pos_mode != 0U)
        {
          LOG_Printf("iadc: SKIPPED -- position servo active; send 'O' to disable first\r\n");
        }
        else
        {
          extern volatile int32_t g_iadc_speed_rpm;
          int32_t rpm = g_iadc_speed_rpm;
          if (rpm < 0)   { rpm = 0; }
          if (rpm > 500) { rpm = 500; }              /* same clamp as 's<rpm>' */
          int32_t oa = 0, ob = 0, oc = 0;
          Ropetow_GetOffsets(&oa, &ob, &oc);
          if (rpm == 0)
          {
            MC_ProgramTorqueRampMotor1_F(0.0f, 0U);  /* zero current commanded */
            osDelay(50U);                            /* let residual current decay */
          }
          else
          {
            /* spin to a constant speed and WAIT until it actually stabilizes before
               sampling (at speed the phase currents are AC: mean ~0, pkpk = current
               amplitude). Poll the measured speed and require it within tolerance
               for a sustained window; bail after a timeout so a stuck ramp can't
               hang the logger. */
            int32_t  tol    = (rpm * 3) / 100;       /* +/-3% of target ... */
            uint32_t t0     = HAL_GetTick();
            uint16_t stable = 0U;
            if (tol < 3) { tol = 3; }                /* ... but at least +/-3 rpm */
            MC_ProgramSpeedRampMotor1((int16_t)((int32_t)rpm * SPEED_UNIT / U_RPM), 1000U);
            for (;;)
            {
              int32_t meas = (int32_t)MC_GetMecSpeedAverageMotor1() * U_RPM / SPEED_UNIT;
              int32_t e    = meas - rpm;
              if (e < 0) { e = -e; }
              stable = (e <= tol) ? (uint16_t)(stable + 1U) : 0U;
              if (stable >= 15U) { break; }          /* ~300 ms continuously in band */
              if ((HAL_GetTick() - t0) > 5000U)
              {
                LOG_Printf("iadc: speed did NOT stabilize (meas=%ld tgt=%ld); sampling anyway\r\n",
                           (long)meas, (long)rpm);
                break;
              }
              LOG_Process();
              osDelay(20U);
            }
          }
          LOG_Printf("iadc_start n=64 (k,Ia,Ib,Ic s16) speed=%ld offsets A=%ld B=%ld C=%ld\r\n",
                     (long)rpm, (long)oa, (long)ob, (long)oc);
          int32_t sa = 0, sb = 0, sc = 0;
          int32_t mnA = 32767, mxA = -32768, mnB = 32767, mxB = -32768, mnC = 32767, mxC = -32768;
          for (int k = 0; k < 64; k++)
          {
            int16_t ia = FOCVars[M1].Iab.a;
            int16_t ib = FOCVars[M1].Iab.b;
            int16_t ic = (int16_t)(-(ia + ib));
            LOG_Printf("%d,%d,%d,%d\r\n", k, (int)ia, (int)ib, (int)ic);
            sa += ia; sb += ib; sc += ic;
            if (ia < mnA) { mnA = ia; }  if (ia > mxA) { mxA = ia; }
            if (ib < mnB) { mnB = ib; }  if (ib > mxB) { mxB = ib; }
            if (ic < mnC) { mnC = ic; }  if (ic > mxC) { mxC = ic; }
            for (uint16_t g = 0U; (LOG_Pending() > 0U) && (g < 200U); g++)
            { LOG_Process(); osDelay(1U); }
            osDelay(2U);
          }
          LOG_Printf("iadc_end mean A=%ld B=%ld C=%ld pkpk A=%d B=%d C=%d\r\n",
                     (long)(sa / 64), (long)(sb / 64), (long)(sc / 64),
                     (int)(mxA - mnA), (int)(mxB - mnB), (int)(mxC - mnC));
          if (rpm != 0) { MC_ProgramSpeedRampMotor1(0, 500U); }  /* stop after sampling */
        }
      }
    }

    /* Position-servo telemetry: while the position mode is engaged, print target
       vs measured angle (and error in degrees) at ~5 Hz so the servo can be tuned
       over the serial link. The PD loop itself runs in the 1 kHz MF hook. */
    {
      extern volatile uint8_t g_pos_mode;
      extern volatile int32_t g_pos_counts, g_pos_target;
      extern volatile uint8_t g_cogg_cal_state;
      static uint32_t pos_log_tick = 0U;
      /* suppress the [pos] line during cogging cal (the servo drives the sweep) */
      if ((g_pos_mode != 0U) && (g_cogg_cal_state == 0U) && ((HAL_GetTick() - pos_log_tick) >= 200U))
      {
        pos_log_tick = HAL_GetTick();
        int32_t err   = g_pos_target - g_pos_counts;
        /* counts -> deci-degrees (16384 counts/rev): deg*10 = counts*3600/16384 */
        int32_t edd   = (int32_t)(((int64_t)err * 3600) / 16384);
        LOG_Printf("[pos] tgt=%ld cur=%ld err=%ld (%ld.%01ld deg)\r\n",
                   (long)g_pos_target, (long)g_pos_counts, (long)err,
                   (long)(edd / 10), (long)(edd < 0 ? -edd % 10 : edd % 10));
      }
    }

    /* Live raw-encoder monitor ('r'): compact angle/AGC/flags each iteration so you
       can watch the sensor while hand-turning. Motor must be STOPPED (the MF hook
       owns hspi1 in RUN). Toggle off with 'r' again. */
    {
      extern volatile uint8_t g_enc_mon;
      if (g_enc_mon != 0U)
      {
        if (MC_GetSTMStateMotor1() == RUN)
        {
          LOG_Printf("enc mon: STOP the motor first (SPI shared with the FOC loop)\r\n");
          g_enc_mon = 0U;
        }
        else
        {
          AS5047_LogAngle(&hspi1);
          for (uint16_t guard = 0U; (LOG_Pending() > 0U) && (guard < 200U); guard++)
          { LOG_Process(); osDelay(2U); }
          osDelay(80U);
          continue;
        }
      }
    }

    /* AGC-vs-position sweep ('a'): log AS5047 AGC/MAGL/MAGH + angle ~24x over ~3 s.
       Spin the shaft slowly during this. Flat AGC (~246 everywhere) => uniform
       under-field (magnet too weak / air-gap too large). AGC that swings with the
       logged angle => eccentric / off-axis mount. See plan Phase 0. */
    {
      extern volatile uint8_t g_agc_log_req;
      if (g_agc_log_req != 0U)
      {
        g_agc_log_req = 0U;
        /* Motor must be STOPPED: the MF hook reads the AS5047 on hspi1 while in RUN,
           and a second reader here would race the SPI. Turn the shaft BY HAND. */
        if (MC_GetSTMStateMotor1() == RUN)
        {
          LOG_Printf("agc sweep: STOP the motor first (turn shaft by hand)\r\n");
          continue;
        }
        LOG_Printf("agc sweep: turn shaft slowly by hand now (24 samples, ~3 s)...\r\n");
        for (uint8_t k = 0U; k < 24U; k++)
        {
          AS5047_LogStatus(&hspi1);
          for (uint16_t guard = 0U; (LOG_Pending() > 0U) && (guard < 200U); guard++)
          { LOG_Process(); osDelay(2U); }
          osDelay(120U);
        }
        LOG_Printf("agc sweep: done\r\n");
        continue;
      }
    }

    /* Anti-cogging calibration arm ('y'): clear accumulators and start binning the
       measured Iq by mechanical position (done in the MF hook). Run a slow constant
       speed and let it sweep several revolutions, then send 'Y' to stop + dump. */
    {
      extern volatile uint8_t g_cogg_cal_req;
      extern void Ropetow_CoggCalArm(void);
      if ((g_cogg_cal_req != 0U) && (MC_GetSTMStateMotor1() == RUN))
      {
        g_cogg_cal_req = 0U;
        Ropetow_CoggCalArm();
        LOG_Printf("cogg cal: probing cable (~20 deg)... then auto-sweep (free shaft!). 'Y'=abort\r\n");
      }
      {
        extern volatile uint8_t g_cogg_probe_fail;
        if (g_cogg_probe_fail != 0U)
        {
          g_cogg_probe_fail = 0U;
          LOG_Printf("cogg cal ABORTED: cable not free (probe stalled) -- add slack or detach the cable\r\n");
        }
      }
    }
    /* 'm' -> more ILC refine passes on the EXISTING map (keep refining until smooth). */
    {
      extern volatile uint8_t g_cogg_refine_req;
      extern volatile uint8_t g_cogg_cal_state;
      if ((g_cogg_refine_req != 0U) && (MC_GetSTMStateMotor1() == RUN))
      {
        g_cogg_refine_req = 0U;
        if (g_cogg_cal_state == 0U)   /* only when fully idle (after any dump finishes) */
        {
          g_cogg_cal_state = 4U;   /* PositionControl runs the refine passes */
          LOG_Printf("cogg refine: more ILC passes on current map (free shaft) -- ~80s\r\n");
        }
      }
    }

    if ((g_step_request != 0U) && (g_step_state == 0U) &&
        (MC_GetSTMStateMotor1() == RUN))
    {
      g_step_request = 0U;
#if STEP_MODE == 2
      /* Iq-ripple capture: motor already holds RIPPLE_SPEED_RPM. Just arm the HF
         capture (q-axis: Iqref vs measured Iq) at the decimated rate -- NO step,
         NO injection. The dump is FFT'd on the host to find the ripple frequency. */
      g_step_mode = 0U;            /* HF-rate capture path */
      g_step_axis = 1U;            /* log Iqref.q / Iq.q   */
      g_cap_decim = RIPPLE_DECIM;
      g_step_idx = 0U; g_step_state = 1U;
      LOG_Printf("ripple: capturing Iq @ %d rpm, %u Hz...\r\n",
                 (int)RIPPLE_SPEED_RPM, (unsigned)(ISR_FREQUENCY_HZ / RIPPLE_DECIM));
#elif STEP_MODE == 1
      /* Speed-loop step: motor already runs at SPEED_BASE_RPM; capture a baseline
         then step the speed reference to SPEED_STEP_RPM. Logged at 1 kHz (MF). */
      g_step_mode = 1U;
      g_step_idx = 0U; g_step_state = 1U;                /* arm (baseline @ SPEED_BASE) */
      osDelay(SPEED_BASELINE_MS);
      MC_ProgramSpeedRampMotor1((int16_t)((int32_t)SPEED_STEP_RPM * SPEED_UNIT / U_RPM), 0U);
      LOG_Printf("step: speed %d -> %d rpm, capturing @ 1 kHz...\r\n",
                 (int)SPEED_BASE_RPM, (int)SPEED_STEP_RPM);
#else
      /* Current-loop step: pin the chosen axis (q=torque or d=hold), short baseline
         at STEP_FROM_A, then step to STEP_TO_A. HF ISR logs ref vs measured @25 kHz. */
      g_step_mode = 0U;
      g_step_axis = STEP_AXIS_Q;
      g_inj_s16 = (int16_t)(STEP_FROM_A * (float)CURRENT_CONV_FACTOR); /* baseline */
      g_inj_override = 1U;
      osDelay(20U);                          /* settle baseline BEFORE arming */
      g_step_idx = 0U; g_step_state = 1U;                              /* arm capture */
      osDelay(STEP_BASELINE_MS);
      g_inj_s16 = (int16_t)(STEP_TO_A * (float)CURRENT_CONV_FACTOR);   /* inject step */
      LOG_Printf("step: %c-axis %d -> %d mA, capturing @ %u kHz...\r\n",
                 (g_step_axis ? 'q' : 'd'),
                 (int)(STEP_FROM_A * 1000.0f), (int)(STEP_TO_A * 1000.0f),
                 (unsigned)(ISR_FREQUENCY_HZ / 1000U / STEP_DECIM));
#endif
    }

    /* Step-response dump (drain-safe): idx,ref,meas (current=s16, speed=rpm). */
    if (g_step_state == 2U)
    {
      static uint16_t sd = 0U;
      uint16_t n = g_step_idx;
      uint16_t end = (uint16_t)(sd + 8U);
      char axc = (g_step_mode ? 's' : (g_step_axis ? 'q' : 'd'));
      unsigned rate_hz = (g_step_mode ? (SPEED_LOOP_FREQUENCY_HZ / SPEED_CAP_DECIM)
                                      : (ISR_FREQUENCY_HZ / g_cap_decim));
      if (end > n) { end = n; }
      if (sd == 0U)
      {
        /* capture done -> stop driving the step IMMEDIATELY: current -> release,
           speed -> ramp back to baseline. */
        if (g_step_mode == 0U) { g_inj_s16 = 0; }
        else { MC_ProgramSpeedRampMotor1((int16_t)((int32_t)SPEED_BASE_RPM * SPEED_UNIT / U_RPM), 0U); }
        LOG_Printf("step_start n=%u hz=%u axis=%c\r\n", (unsigned)n, rate_hz, axc);
      }
      for (; sd < end; sd++)
      { LOG_Printf("%u,%d,%d\r\n", (unsigned)sd, (int)g_step_ref[sd], (int)g_step_iq[sd]); }
      if (sd >= n)
      {
        LOG_Printf("step_end\r\n");
        sd = 0U; g_step_state = 0U;   /* re-arm: 'g' can trigger again (was stuck at 3 = once/boot) */
        if (g_step_mode == 0U) { g_inj_override = 0U; }
      }
      for (uint16_t guard = 0U; (LOG_Pending() > 0U) && (guard < 200U); guard++)
      {
        LOG_Process();
        osDelay(2U);
      }
      continue;
    }

    /* Anti-cogging map dump (drain-safe): per-bin mean of the measured Iq the loop
       fought, indexed by mechanical position. Host cogging.py parses this (run it
       once per direction, then combine). Format mirrors cal_start/step_start. */
    {
      extern volatile uint8_t g_cogg_cal_state;
      extern volatile uint8_t g_cogg_harm_enable;
      extern void Ropetow_CoggCalGet(uint16_t bin, int16_t *mean, uint16_t *count);
      extern void Ropetow_CoggHarmonicFit(void);
      if (g_cogg_cal_state == 2U)
      {
        static uint16_t gd = 0U;
        uint16_t end = (uint16_t)(gd + 8U);
        if (end > (uint16_t)COGG_NBINS) { end = (uint16_t)COGG_NBINS; }
        if (gd == 0U)
        {
          if (g_cogg_harm_enable != 0U) { Ropetow_CoggHarmonicFit(); }  /* denoise once before dumping */
          {
            extern int16_t g_cogg_lut[];   /* peak of the FINAL map = exactly what 'X' will save */
            int16_t pk = 0; uint16_t pb = 0U;
            for (uint16_t i = 0U; i < (uint16_t)COGG_NBINS; i++)
            {
              int16_t v = g_cogg_lut[i]; int16_t a = (v < 0) ? (int16_t)(-v) : v;
              if (a > pk) { pk = a; pb = i; }
            }
            LOG_Printf("[cogg] cal done: peak=%d@bin%u  (compare to boot 'restored peak')\r\n",
                       (int)pk, (unsigned)pb);
          }
          LOG_Printf("cogg_start nbins=%u harm=%u\r\n", (unsigned)COGG_NBINS, (unsigned)g_cogg_harm_enable);
        }
        for (; gd < end; gd++)
        {
          int16_t  mean = 0; uint16_t cnt = 0U;
          Ropetow_CoggCalGet(gd, &mean, &cnt);
          LOG_Printf("%u,%d,%u\r\n", (unsigned)gd, (int)mean, (unsigned)cnt);
        }
        if (gd >= (uint16_t)COGG_NBINS) { LOG_Printf("cogg_end\r\n"); gd = 0U; g_cogg_cal_state = 0U; }
        for (uint16_t guard = 0U; (LOG_Pending() > 0U) && (guard < 200U); guard++)
        {
          LOG_Process();
          osDelay(2U);
        }
        continue;
      }
    }

#if BOOT_OPENLOOP
    const int32_t cal_target_rpm = BOOT_OL_SPEED_RPM;
#else
    const int32_t cal_target_rpm = BOOT_SPEED_RPM;
#endif
    int32_t spd_now = (int32_t)MC_GetMecSpeedAverageMotor1() * U_RPM / SPEED_UNIT;
    int32_t spd_err = spd_now - cal_target_rpm;
    if (MC_GetSTMStateMotor1() != RUN) { g_idx_have = 0U; }

    /* INL capture: trigger only after the speed has been STEADY at target
       (within +/-15 rpm) for ~3 s, so the startup/overshoot transient is over. */
    if ((MC_GetSTMStateMotor1() == RUN) && (spd_err > -15) && (spd_err < 15)) { run_ticks++; }
    else { run_ticks = 0U; }
    if ((run_ticks >= (3000U / APP_LOOP_PERIOD_MS)) && (g_cal_state == 0U))
    {
      g_cal_idx = 0U; g_cal_state = 1U;
      LOG_Printf("cal: speed steady, capturing angle @ ~100 Hz...\r\n");
    }

    /* INL dump: emit a small chunk, then DRAIN THE RING TO EMPTY before producing
       the next chunk, so the 2048-byte log buffer can never overflow (the previous
       version pushed ~144 B/iter but LOG_Process drained less per call -> the ring
       filled after ~400 lines and LOG_Printf dropped the rest -> corrupt CSV).
       The continue suppresses status logs while dumping so the CSV stays clean. */
    if (g_cal_state == 2U)
    {
      static uint16_t cd = 0U;
      uint16_t n = g_cal_idx;
      uint16_t end = (uint16_t)(cd + 8U);
      if (end > n) { end = n; }
      if (cd == 0U) { LOG_Printf("cal_start n=%u\r\n", (unsigned)n); }
      for (; cd < end; cd++) { LOG_Printf("%u,%u\r\n", (unsigned)cd, (unsigned)g_cal_raw[cd]); }
      if (cd >= n) { LOG_Printf("cal_end\r\n"); cd = 0U; g_cal_state = 3U; }
      /* drain-to-empty: CDC sends <=64 B per completed transfer (~1 ms at FS),
         so loop with a short yield until the ring clears (bounded for safety). */
      for (uint16_t guard = 0U; (LOG_Pending() > 0U) && (guard < 200U); guard++)
      {
        LOG_Process();
        osDelay(2U);
      }
      continue;
    }

    /* Encoder-alignment marker: proves the MCSDK EAC alignment actually ran this
       boot (the small startup turn) even if you missed it during USB re-enumeration. */
    {
      extern volatile uint8_t g_enc_align_evt;
      if (g_enc_align_evt != 0U) { g_enc_align_evt = 0U; LOG_Printf("[align] encoder alignment complete\r\n"); }
    }

    /* One-shot at boot: report what the saved calibration restored, so a "cogging
       came back after reset" can be diagnosed at a glance -- peak!=0 proves the map
       loaded intact; clamp/gain show the knobs were restored (not reset to default). */
    {
      extern volatile uint8_t g_cogg_from_flash;
      extern volatile int16_t g_cogg_clamp;
      extern volatile float   g_cogg_gain;
      extern int16_t          g_cogg_lut[];
      static uint8_t cogg_boot_logged = 0U;
      if (cogg_boot_logged == 0U)
      {
        cogg_boot_logged = 1U;
        if (g_cogg_from_flash != 0U)
        {
          int16_t pk = 0; uint16_t pkbin = 0U;
          for (uint16_t i = 0U; i < (uint16_t)COGG_NBINS; i++)
          {
            int16_t v = g_cogg_lut[i];
            int16_t a = (v < 0) ? (int16_t)(-v) : v;
            if (a > pk) { pk = a; pkbin = i; }
          }
          LOG_Printf("[cogg] flash cal restored: peak=%d@bin%u clamp=%d gain=%d%%\r\n",
                     (int)pk, (unsigned)pkbin, (int)g_cogg_clamp, (int)(g_cogg_gain * 100.0f));
        }
      }
    }

    /* Anti-cogging map persistence: 'X' saves the map, 'n' erases it. A flash
       erase/program STALLS the CPU for tens of ms (code fetch from flash blocks),
       which both breaks a live FOC loop AND wedges the USB/CDC link so the serial
       never resumes in place. So we AUTO-STOP the motor, wait for IDLE (PWM off =
       safe), do the flash op, then REBOOT: a clean reset re-enumerates USB (serial
       reconnects) and re-runs the boot map-load -- the exact recovery a manual reset
       already produces. On failure we don't reboot (keeps the freshly-cal'd RAM map
       so you can retry the save). */
    {
      extern volatile uint8_t g_cogg_save_req;
      extern volatile uint8_t g_cogg_erase_req;
      extern uint8_t Ropetow_CoggSaveToFlash(void);
      extern uint8_t Ropetow_CoggEraseFlash(void);
      if ((g_cogg_save_req != 0U) || (g_cogg_erase_req != 0U))
      {
        uint8_t  do_save = g_cogg_save_req;
        uint16_t guard   = 0U;
        g_cogg_save_req = 0U; g_cogg_erase_req = 0U;

        MC_StopMotor1();                                              /* command stop      */
        while ((MC_GetSTMStateMotor1() != IDLE) && (guard++ < 250U))  /* wait <=1s for IDLE */
        {
          LOG_Process();
          osDelay(4U);
        }

        if (MC_GetSTMStateMotor1() != IDLE)
        {
          /* couldn't reach IDLE -> do NOT touch flash; bring the drive back and bail */
          LOG_Printf("[cogg] %s ABORTED: motor did not stop (state=%d)\r\n",
                     (do_save ? "save" : "erase"), (int)MC_GetSTMStateMotor1());
          (void)MC_AcknowledgeFaultMotor1();
          MC_ProgramTorqueRampMotor1_F(0.0f, 0U);
          (void)MC_StartMotor1();
        }
        else if ((do_save ? Ropetow_CoggSaveToFlash() : Ropetow_CoggEraseFlash()) != 0U)
        {
          /* success -> flush the log over USB, then reboot to reload cleanly. */
          LOG_Printf("[cogg] %s OK -- rebooting to reload...\r\n",
                     (do_save ? "save->flash" : "erase"));
          for (uint16_t f = 0U; (LOG_Pending() > 0U) && (f < 200U); f++) { LOG_Process(); osDelay(2U); }
          osDelay(50U);
          NVIC_SystemReset();                 /* does not return */
        }
        else
        {
          /* flash op failed -> keep the RAM map, bring the drive back so you can retry */
          LOG_Printf("[cogg] %s FAILED -- map kept in RAM, retry\r\n",
                     (do_save ? "save" : "erase"));
          (void)MC_AcknowledgeFaultMotor1();
          MC_ProgramTorqueRampMotor1_F(0.0f, 0U);
          (void)MC_StartMotor1();
        }
      }
    }

    {
    extern volatile uint8_t g_cogg_cal_state;
    extern volatile uint8_t g_cogg_cal_pass;
    extern volatile uint8_t g_cogg_cal_target;
    if (g_cogg_cal_state == 1U)
    {
      /* CALIBRATING: show only the cal progress, suppress the normal telemetry flood. */
      static uint32_t cogg_log_tick = 0U;
      if ((HAL_GetTick() - cogg_log_tick) >= 500U)
      {
        extern volatile int16_t g_avg_iq;
        cogg_log_tick = HAL_GetTick();
        LOG_Printf("[cogg] pass %u/%u  Iq=%d  (sweeping)\r\n",
                   (unsigned)(g_cogg_cal_pass + 1U), (unsigned)g_cogg_cal_target, (int)g_avg_iq);
      }
    }
    else if (g_cogg_cal_state == 0U)
    {
    /* All periodic telemetry is the single [m] line in motor_status_log(). */
    motor_status_log();
    }  /* end else-if (cal idle) */
    }  /* end cal-state telemetry gate */
    LOG_Process();
    /* ESP-link TX/telemetry/watchdog now run at 50 Hz from the MF hook
       (Ropetow_EspLinkService) -- keeps a single TX producer and steady timing. */
    osDelay(APP_LOOP_PERIOD_MS);
  }
}

/* USER CODE END 4 */

__weak void startMediumFrequencyTask(void const * argument)
{
  /* init code for USB_Device */
  MX_USB_Device_Init();
  for(;;)
  {
    osDelay(1);
  }
}

void HAL_TIM_PeriodElapsedCallback(TIM_HandleTypeDef *htim)
{
  if (htim->Instance == TIM6)
  {
    HAL_IncTick();
  }
}

void Error_Handler(void)
{
  __disable_irq();
  while (1)
  {
  }
}
